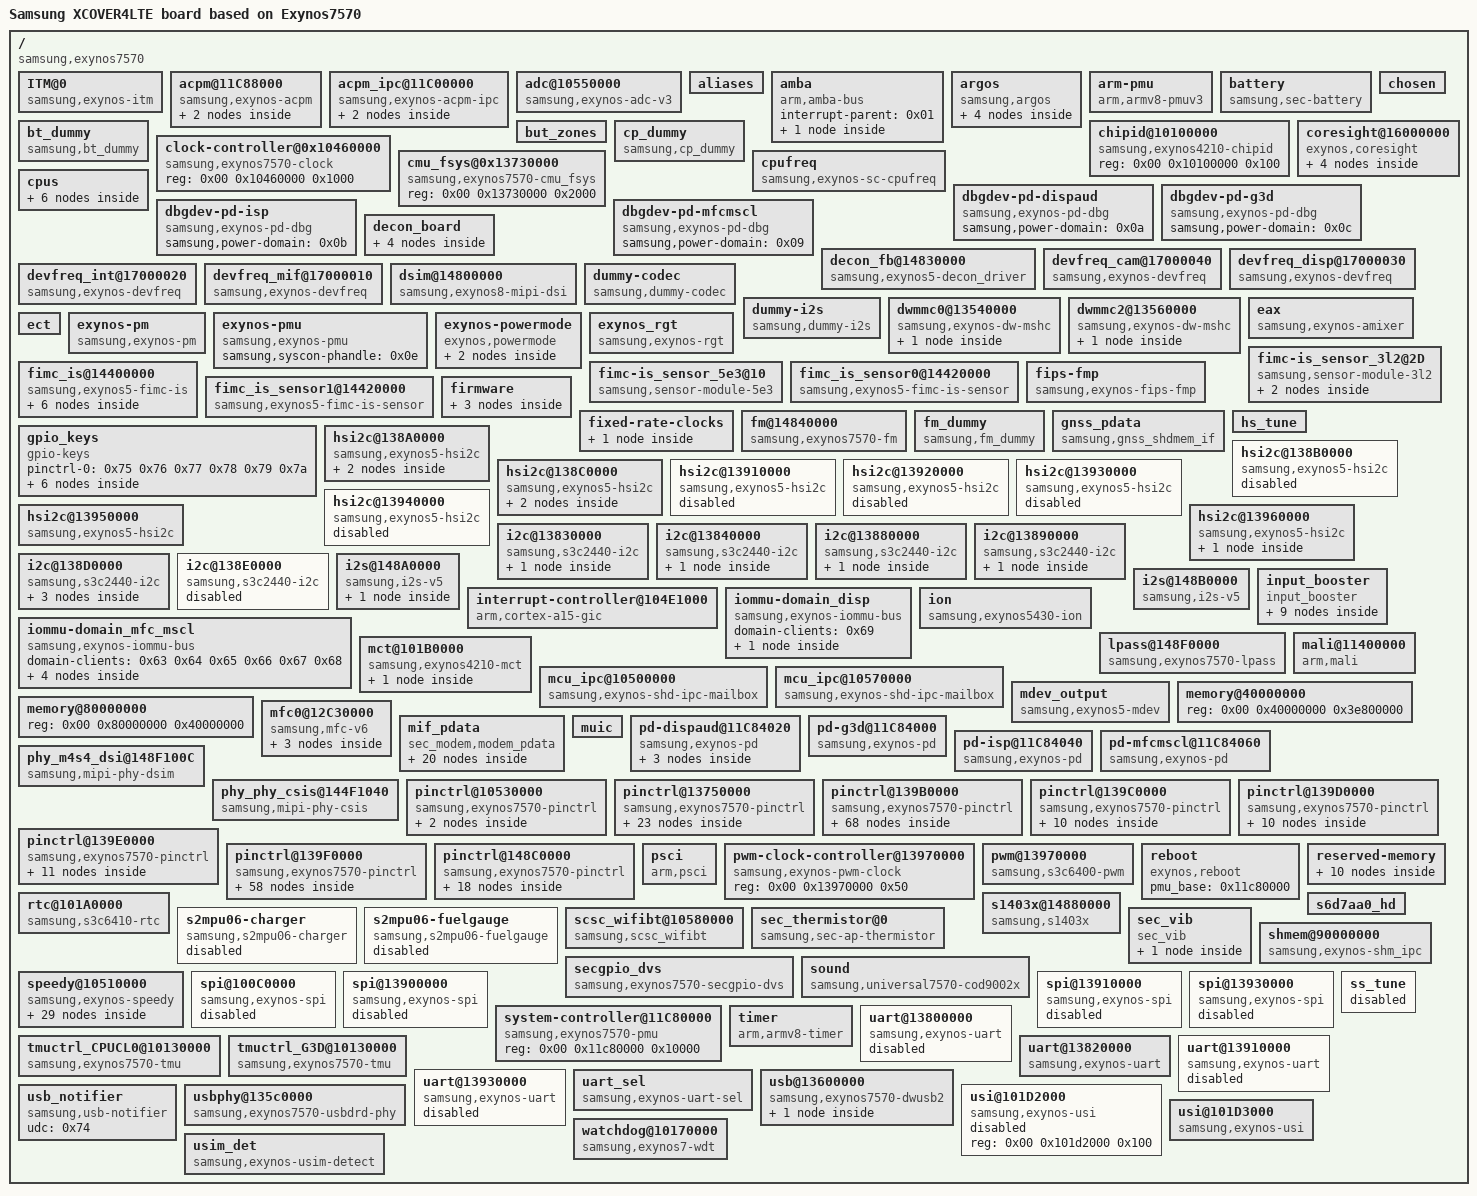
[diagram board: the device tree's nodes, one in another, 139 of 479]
/dts-v1/;

/memreserve/	0x000000007e700000 0x0000000000100000;
/ {
	#address-cells = <0x02>;
	#size-cells = <0x01>;
	compatible = "samsung,exynos7570\0samsung,exynos4210";
	interrupt-parent = <0x01>;
	model = "Samsung XCOVER4LTE board based on Exynos7570";
	model_info-chip = <0x1d92>;
	model_info-hw_rev = <0x00>;
	model_info-hw_rev_end = <0x00>;
	model_info-platform = "android";
	model_info-subtype = "samsung";

	ITM@0 {
		compatible = "samsung,exynos-itm";
	};

	acpm@11C88000 {
		#address-cells = <0x02>;
		#size-cells = <0x01>;
		compatible = "samsung,exynos-acpm";
		debug_logging_level = <0x00>;
		dump_base = <0x2046000>;
		dump_size = <0x3800>;
		log_base = <0x2047700>;
		log_buff_len = <0x17c>;
		log_buff_size = <0x10>;
		logging_period = <0x1f4>;
		reg = <0x00 0x11c88000 0x1000>;
		time_len = <0x20>;

		plugins {

			framework {
				acpm-ipc-channel = <0x80>;
				attach = <0x02>;
				id = <0x00>;
			};
		};
	};

	acpm_ipc@11C00000 {
		#address-cells = <0x02>;
		#size-cells = <0x01>;
		compatible = "samsung,exynos-acpm-ipc";
		interrupts = <0x00 0x16 0x00>;
		reg = <0x00 0x11c00000 0x1000>;

		channels {
			max_buff_size = <0x300>;
			polling = <0x01>;

			framework@0x02047400 {
				buff_len = <0x08>;
				buff_size = <0x0c>;
				channel_id = <0x00>;
				direction_buff = <0x19c>;
				linux,phandle = <0x80>;
				phandle = <0x80>;
				rx_buff = <0x2047400>;
				tx_buff = <0x2047480>;
			};
		};
	};

	adc@10550000 {
		#io-channel-cells = <0x01>;
		clock-names = "gate_adcif";
		clocks = <0x10 0x0a>;
		compatible = "samsung,exynos-adc-v3";
		interrupts = <0x00 0x18b 0x00>;
		io-channel-ranges;
		linux,phandle = <0x43>;
		phandle = <0x43>;
		reg = <0x00 0x10550000 0x1000>;
	};

	aliases {
		decon0 = "/decon_fb@14830000";
		dsim0 = "/dsim@14800000";
		hsi2c0 = "/hsi2c@13950000";
		hsi2c1 = "/hsi2c@13960000";
		hsi2c2 = "/hsi2c@138A0000";
		hsi2c3 = "/hsi2c@138C0000";
		hsi2c4 = "/hsi2c@138B0000";
		hsi2c5 = "/hsi2c@13910000";
		hsi2c6 = "/hsi2c@13920000";
		hsi2c7 = "/hsi2c@13930000";
		hsi2c8 = "/hsi2c@13940000";
		mfc0 = "/mfc0@12C30000";
		mshc0 = "/dwmmc0@13540000";
		mshc2 = "/dwmmc2@13560000";
		pinctrl0 = "/pinctrl@139F0000";
		pinctrl1 = "/pinctrl@148C0000";
		pinctrl2 = "/pinctrl@139E0000";
		pinctrl3 = "/pinctrl@13750000";
		pinctrl4 = "/pinctrl@10530000";
		pinctrl5 = "/pinctrl@139C0000";
		pinctrl6 = "/pinctrl@139B0000";
		pinctrl7 = "/pinctrl@139D0000";
		scaler0 = "/iommu-domain_mfc_mscl/scaler@12C10000";
		spi0 = "/spi@100C0000";
		spi1 = "/spi@13900000";
		spi2 = "/spi@13910000";
		spi3 = "/spi@13930000";
		tmuctrl0 = "/tmuctrl_CPUCL0@10130000";
		tmuctrl1 = "/tmuctrl_G3D@10130000";
		uart1 = "/uart@13800000";
		uart2 = "/uart@13820000";
		uart3 = "/uart@13910000";
		uart4 = "/uart@13930000";
	};

	amba {
		#address-cells = <0x02>;
		#size-cells = <0x01>;
		compatible = "arm,amba-bus";
		interrupt-parent = <0x01>;
		ranges;

		pdma0@10490000 {
			#dma-cells = <0x01>;
			#dma-channels = <0x08>;
			#dma-requests = <0x20>;
			clock-names = "apb_pclk";
			clocks = <0x10 0x32>;
			compatible = "arm,pl330\0arm,primecell";
			interrupts = <0x00 0x17f 0x00>;
			linux,phandle = <0x3c>;
			phandle = <0x3c>;
			reg = <0x00 0x10490000 0x1000>;
		};
	};

	argos {
		#address-cells = <0x01>;
		compatible = "samsung,argos";

		boot_device@1 {
			net_boost,label = "IPC";
			net_boost,node = "rmnet0 rmnet1 rmnet2 rmnet3 rmnet4 rmnet5 rmnet6 rmnet7 umts_dm0";
			net_boost,table = <0x01 0x00 0x00 0x00 0x00 0x00 0x01 0x14 0xca648 0x00 0x65900 0x186a0 0x00 0x01 0x32 0xfde80 0x00 0xc96a8 0x186a0 0x00 0x01 0x64 0x15d1f0 0x00 0xc96a8 0x186a0 0x00 0x01>;
			net_boost,table_size = <0x04>;
		};

		boot_device@2 {
			net_boost,label = "USB";
			net_boost,node = "rndis0";
			net_boost,table = <0x01 0x00 0x00 0x00 0x00 0x00 0x01>;
			net_boost,table_size = <0x01>;
		};

		boot_device@3 {
			net_boost,label = "P2P";
			net_boost,node = "p2p-wlan0-0";
			net_boost,table = <0x1e 0x137090 0x00 0x65518 0x00 0x00 0x00 0x32 0x1506d0 0x00 0x65518 0x00 0x00 0x00 0x5a 0x1506d0 0x00 0xa2990 0x00 0x01 0x01>;
			net_boost,table_size = <0x03>;
		};

		boot_device@4 {
			net_boost,label = "WIFI";
			net_boost,node = "wlan0";
			net_boost,table = <0x0a 0xfde80 0x00 0x65518 0x00 0x00 0x00 0x3c 0x1506d0 0x00 0xa2990 0x00 0x01 0x01 0x78 0x1506d0 0x00 0xa2990 0x00 0x01 0x01>;
			net_boost,table_size = <0x03>;
		};
	};

	arm-pmu {
		compatible = "arm,armv8-pmuv3";
		interrupts = <0x00 0x32 0x04 0x00 0x33 0x04 0x00 0x34 0x04 0x00 0x35 0x04>;
	};

	battery {
		#io-channel-cells = <0x01>;
		battery,adc_check_count = <0x05>;
		battery,age_data = <0x00 0x10fe 0x10b8 0x109a 0x5d 0x1c 0x10ea 0x10a4 0x1086 0x5b 0x24 0x10d6 0x1090 0x1072 0x59>;
		battery,battery_check_type = <0x05>;
		battery,battery_full_capacity = <0xaf0>;
		battery,cable_check_type = <0x04>;
		battery,cable_source_type = <0x01>;
		battery,call_event_siop_level = <0x32>;
		battery,charger_name = "s2mpu06-charger";
		battery,charging_reset_time = <0x00>;
		battery,charging_total_time = <0x5460>;
		battery,check_adc_max = <0x5a0>;
		battery,check_adc_min = <0x00>;
		battery,check_count = <0x00>;
		battery,chg_charging_limit_current = <0x514>;
		battery,chg_charging_limit_current_2nd = <0x514>;
		battery,chg_float_voltage = <0x10fe>;
		battery,chg_gpio_full_check = <0x00>;
		battery,chg_high_temp_1st = <0x212>;
		battery,chg_high_temp_2nd = <0x212>;
		battery,chg_high_temp_recovery = <0x20d>;
		battery,chg_polarity_full_check = <0x01>;
		battery,chg_skip_check_capacity = <0x0a>;
		battery,chg_skip_check_time = <0x258>;
		battery,chip_vendor = "LSI";
		battery,enable_water_resistance;
		battery,expired_time = <0x35e8>;
		battery,fast_charging_current = <0x708 0x00 0x00 0x708 0x1cc 0x4b0 0x3e8 0x1cc 0x4b0 0x00 0x4b0 0x4b0 0x4b0 0x4b0 0x4b0 0x00 0x00 0x190 0x2bc 0x4b0 0x12c 0x3e8 0x4b0 0x00 0x708 0x708 0x3e8 0x708 0x50 0x708 0x3e8 0x578 0x00 0x3e8 0x4b0 0x4b0 0x00>;
		battery,fuelgauge_name = "s2mpu06-fuelgauge";
		battery,full_check_count = <0x01>;
		battery,full_check_current_1st = <0x118 0x00 0x00 0x118 0x118 0x118 0x118 0x118 0x118 0x00 0x118 0x118 0x118 0x118 0x118 0x00 0x00 0x118 0x118 0x118 0x118 0x118 0x118 0x00 0x118 0x118 0x118 0x118 0x00 0x118 0x118 0x118 0x00 0x118 0x118 0x118 0x00>;
		battery,full_check_current_2nd = <0x8c 0x00 0x00 0x8c 0x8c 0x8c 0x8c 0x8c 0x8c 0x00 0x8c 0x8c 0x8c 0x8c 0x8c 0x00 0x00 0x8c 0x8c 0x8c 0x8c 0x8c 0x8c 0x00 0x8c 0x8c 0x8c 0x8c 0x00 0x8c 0x8c 0x8c 0x00 0x8c 0x8c 0x8c 0x00>;
		battery,full_check_type = <0x07>;
		battery,full_check_type_2nd = <0x07>;
		battery,full_condition_soc = <0x5d>;
		battery,full_condition_type = <0x0f>;
		battery,full_condition_vcell = <0x109a>;
		battery,inbat_voltage = <0x01>;
		battery,inbat_voltage_table_adc = <0xc30 0xc1d 0xbf5 0xbde 0xbb9 0xb8c 0xb68 0xb47 0xb28 0xafe 0xae9 0xac2 0xaa0 0xa75 0xa51 0xa35 0xa0c 0x9e3 0x9c6 0x9a3 0x984>;
		battery,inbat_voltage_table_data = <0x1b6 0x1b3 0x1ae 0x1a9 0x1a4 0x19f 0x19a 0x195 0x190 0x18b 0x186 0x181 0x17c 0x177 0x172 0x16d 0x168 0x163 0x15e 0x159 0x154>;
		battery,input_current_limit = <0x5dc 0x1cc 0x1cc 0x60e 0x1cc 0x384 0x3e8 0x1cc 0x3e8 0x00 0x334 0x334 0x334 0x3e8 0x3e8 0x00 0x00 0x190 0x2bc 0x3e8 0x12c 0x3e8 0x3e8 0x00 0x3e8 0x60e 0x3e8 0x60e 0x50 0x60e 0x3e8 0x3e8 0x3e8 0x3e8 0x334 0x334 0x1cc>;
		battery,monitor_initial_count = <0x00>;
		battery,ovp_uvlo_check_type = <0x03>;
		battery,polling_time = <0x0a 0x1e 0x1e 0x1e 0xe10>;
		battery,polling_type = <0x01>;
		battery,recharge_check_count = <0x02>;
		battery,recharge_condition_soc = <0x62>;
		battery,recharge_condition_type = <0x04>;
		battery,recharge_condition_vcell = <0x10b8>;
		battery,recharging_expired_time = <0x1518>;
		battery,recharging_total_time = <0x1518>;
		battery,standard_curr = <0x643>;
		battery,swelling_block_time = <0x258>;
		battery,swelling_drop_float_voltage = <0x1036>;
		battery,swelling_high_rechg_voltage = <0xfa0>;
		battery,swelling_high_temp_block = <0x19a>;
		battery,swelling_high_temp_current = <0x3e8>;
		battery,swelling_high_temp_recov = <0x186>;
		battery,swelling_high_temp_topoff = <0x8c>;
		battery,swelling_low_rechg_voltage = <0xfa0>;
		battery,swelling_low_temp_2step_mode = <0x01>;
		battery,swelling_low_temp_block_1st = <0x96>;
		battery,swelling_low_temp_block_2nd = <0x32>;
		battery,swelling_low_temp_current = <0x294>;
		battery,swelling_low_temp_recov_1st = <0xc8>;
		battery,swelling_low_temp_recov_2nd = <0x64>;
		battery,swelling_low_temp_topoff = <0x8c>;
		battery,technology = <0x02>;
		battery,temp_adc_type = <0x01>;
		battery,temp_check_count = <0x01>;
		battery,temp_check_type = <0x02>;
		battery,temp_high_recovery_lpm = <0x1c2>;
		battery,temp_high_recovery_normal = <0x1c2>;
		battery,temp_high_threshold_lpm = <0x1f4>;
		battery,temp_high_threshold_normal = <0x1f4>;
		battery,temp_highlimit_recovery_lpm = <0x2ee>;
		battery,temp_highlimit_recovery_normal = <0x2ee>;
		battery,temp_highlimit_threshold_lpm = <0x320>;
		battery,temp_highlimit_threshold_normal = <0x320>;
		battery,temp_low_recovery_lpm = <0x32>;
		battery,temp_low_recovery_normal = <0x32>;
		battery,temp_low_threshold_lpm = <0x00>;
		battery,temp_low_threshold_normal = <0x00>;
		battery,temp_table_adc = <0x12c 0x162 0x196 0x1d9 0x22a 0x288 0x2fd 0x345 0x37e 0x3b8 0x40b 0x467 0x4a2 0x4f5 0x53c 0x55e 0x5ae 0x5fe 0x626 0x6ea 0x7d9 0x8c6 0x9b4 0xa05 0xa8a 0xafc 0xb55 0xbb5 0xc28 0xcaa 0xce0 0xd71 0xdf9 0xe62>;
		battery,temp_table_data = <0x384 0x352 0x320 0x2ee 0x2bc 0x28a 0x258 0x23a 0x226 0x212 0x1f4 0x1d6 0x1c2 0x1ae 0x19a 0x190 0x17c 0x168 0x15e 0x12c 0xfa 0xc8 0x96 0x82 0x64 0x46 0x32 0x1e 0x00 0xffffffe2 0xffffffce 0xffffff9c 0xffffff6a 0xffffff38>;
		battery,thermal_source = <0x02>;
		battery,vendor = "SDI SDI";
		battery,wireless_cc_cv = <0x56>;
		battery,wpc_charging_limit_current = <0x1c2>;
		battery,wpc_high_temp = <0x1a4>;
		battery,wpc_high_temp_recovery = <0x19a>;
		compatible = "samsung,sec-battery";
		io-channel-names = "adc-temp";
		io-channel-ranges;
		io-channels = <0x43 0x01>;
		pinctrl-names = "default";
		status = "okay";
	};

	bt_dummy {
		compatible = "samsung,bt_dummy";
		linux,phandle = <0x83>;
		phandle = <0x83>;
		status = "okay";
	};

	but_zones {
		#list-but-cells = <0x03>;
		linux,phandle = <0x44>;
		phandle = <0x44>;
	};

	chipid@10100000 {
		compatible = "samsung,exynos4210-chipid";
		reg = <0x00 0x10100000 0x100>;
	};

	chosen {
		bootargs = "console=ttySAC2,115200 clk_ignore_unused androidboot.hardware=samsungexynos7570 androidboot.selinux=disabled firmware_class.path=/vendor/firmware ess_setup=0x46000000 bcm_setup=0xffffff80f8e00000 androidboot.debug_level=0x4948 reserve-fimc=0";
		linux,initrd-end = <0x421fffff>;
		linux,initrd-start = <0x42000000>;
	};

	clock-controller@0x10460000 {
		#clock-cells = <0x01>;
		compatible = "samsung,exynos7570-clock";
		linux,phandle = <0x10>;
		phandle = <0x10>;
		reg = <0x00 0x10460000 0x1000>;
	};

	cmu_fsys@0x13730000 {
		compatible = "samsung,exynos7570-cmu_fsys\0syscon";
		linux,phandle = <0x62>;
		phandle = <0x62>;
		reg = <0x00 0x13730000 0x2000>;
	};

	coresight@16000000 {
		base = <0x16000000>;
		compatible = "exynos,coresight";
		sjtag-offset = <0x6000>;

		cs_apollo0@400000 {
			dbg-offset = <0x410000>;
			device_type = "cs";
		};

		cs_apollo1@500000 {
			dbg-offset = <0x510000>;
			device_type = "cs";
		};

		cs_apollo2@600000 {
			dbg-offset = <0x610000>;
			device_type = "cs";
		};

		cs_apollo3@700000 {
			dbg-offset = <0x710000>;
			device_type = "cs";
		};
	};

	cp_dummy {
		compatible = "samsung,cp_dummy";
		linux,phandle = <0x82>;
		phandle = <0x82>;
		status = "okay";
	};

	cpufreq {
		cl0_boot_lock_time = <0x2625a00>;
		cl0_boot_max_qos = <0x1506d0>;
		cl0_boot_min_qos = <0x1506d0>;
		cl0_dvfs_domain_name = "dvfs_cpucl0";
		cl0_en_ema = <0x00>;
		cl0_idx_num = <0x11>;
		cl0_max_support_idx = <0x05>;
		cl0_min_support_idx = <0x0e>;
		cl0_regulator = "BUCK1";
		compatible = "samsung,exynos-sc-cpufreq";
	};

	cpus {
		#address-cells = <0x02>;
		#size-cells = <0x00>;

		cpu@0 {
			compatible = "arm,cortex-a53\0arm,armv8";
			cpu-idle-states = <0x0d>;
			device_type = "cpu";
			enable-method = "psci";
			reg = <0x00 0x00>;
		};

		cpu@1 {
			compatible = "arm,cortex-a53\0arm,armv8";
			cpu-idle-states = <0x0d>;
			device_type = "cpu";
			enable-method = "psci";
			reg = <0x00 0x01>;
		};

		cpu@2 {
			compatible = "arm,cortex-a53\0arm,armv8";
			cpu-idle-states = <0x0d>;
			device_type = "cpu";
			enable-method = "psci";
			reg = <0x00 0x02>;
		};

		cpu@3 {
			compatible = "arm,cortex-a53\0arm,armv8";
			cpu-idle-states = <0x0d>;
			device_type = "cpu";
			enable-method = "psci";
			reg = <0x00 0x03>;
		};

		idle-states {
			entry-method = "arm,psci";

			cpu-sleep {
				arm,psci-suspend-param = <0x10000>;
				compatible = "exynos,idle-state";
				desc = "cpu sleep";
				entry-latency-us = <0x23>;
				exit-latency-us = <0x5a>;
				linux,phandle = <0x0d>;
				min-residency-us = <0x2ee>;
				phandle = <0x0d>;
				status = "okay";
			};
		};
	};

	dbgdev-pd-dispaud {
		compatible = "samsung,exynos-pd-dbg";
		samsung,power-domain = <0x0a>;
	};

	dbgdev-pd-g3d {
		compatible = "samsung,exynos-pd-dbg";
		samsung,power-domain = <0x0c>;
	};

	dbgdev-pd-isp {
		compatible = "samsung,exynos-pd-dbg";
		samsung,power-domain = <0x0b>;
	};

	dbgdev-pd-mfcmscl {
		compatible = "samsung,exynos-pd-dbg";
		samsung,power-domain = <0x09>;
	};

	decon_board {
		gpio_blic_on = <0x18 0x02 0x01>;
		gpio_lcd_rst = <0x73 0x00 0x01>;
		gpio_panel_enn = <0x72 0x02 0x01>;
		gpio_panel_enp = <0x72 0x01 0x01>;
		linux,phandle = <0x61>;
		phandle = <0x61>;

		dsim_reset_panel {
			type = "delay,usleep\01000 1100\0gpio,high\0gpio_lcd_rst\0delay,usleep\01000 1100\0gpio,low\0gpio_lcd_rst\0delay,usleep\01000 1100\0gpio,high\0gpio_lcd_rst\0delay,usleep\05000 5100";
		};

		dsim_set_panel_power_disable {
			type = "delay,usleep\05000 6000\0gpio,low\0gpio_lcd_rst\0delay,usleep\05000 6000\0gpio,low\0gpio_panel_enn\0delay,usleep\05000 6000\0gpio,low\0gpio_panel_enp\0delay,usleep\015000 16000\0gpio,low\0gpio_blic_on\0delay,usleep\010000 11000\0regulator,disable\0LCD_1P8";
		};

		dsim_set_panel_power_early {
			type = "regulator,enable\0LCD_1P8\0delay,usleep\01000 2000";
		};

		dsim_set_panel_power_enable {
			type = "gpio,high\0gpio_panel_enp\0delay,usleep\05000 6000\0gpio,high\0gpio_panel_enn\0delay,usleep\010000 11000\0gpio,high\0gpio_blic_on\0delay,usleep\01000 2000";
		};
	};

	decon_fb@14830000 {
		#address-cells = <0x02>;
		#pb-id-cells = <0x00>;
		#size-cells = <0x01>;
		clock-names = "decon_core\0vclk_user\0vclk_leaf";
		clocks = <0x10 0x2bf 0x10 0x2da 0x10 0x2db>;
		compatible = "samsung,exynos5-decon_driver";
		default_win = <0x00>;
		disp-dvfs = <0xc65d400>;
		disp-vclk = <0xbebc200>;
		dsi_mode = <0x00>;
		interrupts = <0x00 0xc9 0x00 0x00 0xca 0x00 0x00 0xcb 0x00 0x00 0x168 0x00>;
		ip_ver = <0x04>;
		linux,phandle = <0x69>;
		max_win = <0x03>;
		mif-vclk = <0xbebc200>;
		n_sink_pad = <0x03>;
		n_src_pad = <0x01>;
		phandle = <0x69>;
		psr_mode = <0x00>;
		ranges;
		reg = <0x00 0x14830000 0x8000>;
		samsung,power-domain = <0x5e>;
		trig_mode = <0x01>;
		vclk-denom = <0x1a1>;
		vclk-num = <0x400>;
	};

	devfreq_cam@17000040 {
		boot_qos_timeout = <0x00>;
		clock-names = "dvfs_cam";
		clocks = <0x10 0x3eb>;
		compatible = "samsung,exynos-devfreq";
		devfreq_domain_name = "dvfs_cam";
		devfreq_type = "cam";
		freq_info = <0x6c660 0x6c660 0x6c660 0x6c660 0x87410 0x6c660>;
		gov_name = "interactive";
		polling_ms = <0x00>;
		reg = <0x00 0x17000040 0x00>;
		reg_name = "BUCK1";
		use_cl_dvfs = "false";
		use_delay_time = "false";
		use_get_dev = "false";
		use_pd_off = "true";
		use_reg = "true";
		use_sw_clk = "false";
		use_tmu = "true";
		volt_info = <0x61a8 0x1312d0 0x00 0x13d620>;
	};

	devfreq_disp@17000030 {
		boot_qos_timeout = <0x28>;
		clock-names = "dvfs_disp";
		clocks = <0x10 0x3ec>;
		compatible = "samsung,exynos-devfreq";
		devfreq_domain_name = "dvfs_disp";
		devfreq_type = "disp";
		freq_info = <0x32c80 0x32c80 0x32c80 0x32c80 0x32c80 0x32c80>;
		gov_name = "interactive";
		polling_ms = <0x00>;
		reg = <0x00 0x17000030 0x00>;
		reg_name = "BUCK1";
		use_cl_dvfs = "false";
		use_delay_time = "false";
		use_get_dev = "false";
		use_pd_off = "false";
		use_reg = "true";
		use_sw_clk = "false";
		use_tmu = "true";
		volt_info = <0x61a8 0x1312d0 0x00 0x13d620>;
	};

	devfreq_int@17000020 {
		boot_qos_timeout = <0x28>;
		clock-names = "dvfs_int";
		clocks = <0x10 0x3ea>;
		compatible = "samsung,exynos-devfreq";
		devfreq_domain_name = "dvfs_int";
		devfreq_type = "int";
		freq_info = <0x72038 0x65518 0x72038 0x65518 0x72038 0x65518>;
		gov_name = "interactive";
		polling_ms = <0x00>;
		reg = <0x00 0x17000020 0x00>;
		reg_name = "BUCK1";
		use_cl_dvfs = "false";
		use_delay_time = "false";
		use_get_dev = "false";
		use_pd_off = "false";
		use_reg = "true";
		use_sw_clk = "false";
		use_tmu = "true";
		volt_info = <0x61a8 0x1312d0 0x00 0x13d620>;
	};

	devfreq_mif@17000010 {
		boot_qos_timeout = <0x28>;
		clock-names = "dvfs_mif\0dvfs_mif_sw";
		clocks = <0x10 0x3e8 0x10 0x3e9>;
		compatible = "samsung,exynos-devfreq";
		delay_time_list = "20";
		devfreq_domain_name = "dvfs_mif";
		devfreq_type = "mif";
		freq_info = <0xa2990 0x65518 0x65518 0x65518 0xa2990 0x65518>;
		gov_name = "interactive";
		polling_ms = <0x00>;
		reg = <0x00 0x17000010 0x00>;
		reg_name = "BUCK1";
		use_cl_dvfs = "false";
		use_delay_time = "true";
		use_get_dev = "false";
		use_pd_off = "false";
		use_reg = "true";
		use_sw_clk = "true";
		use_tmu = "true";
		volt_info = <0x61a8 0x1312d0 0x00 0x13d620>;
	};

	dsim@14800000 {
		clock-names = "dsim_pclk\0dphy_escclk\0dphy_byteclk";
		clocks = <0x10 0x2c0 0x10 0x2d1 0x10 0x2d0>;
		compatible = "samsung,exynos8-mipi-dsi";
		data_lane_cnt = <0x04>;
		decon_board = <0x61>;
		interrupts = <0x00 0xcf 0x00>;
		lcd_info = <0x60>;
		phy-names = "dsim_dphy";
		phys = <0x5f 0x00>;
		reg = <0x00 0x14800000 0x100>;
		samsung,power-domain = <0x5e>;
		status = "okay";
	};

	dummy-codec {
		compatible = "samsung,dummy-codec";
		linux,phandle = <0x87>;
		phandle = <0x87>;
		status = "okay";
	};

	dummy-i2s {
		compatible = "samsung,dummy-i2s";
		status = "okay";
	};

	dwmmc0@13540000 {
		#address-cells = <0x01>;
		#size-cells = <0x00>;
		broken-card-detect;
		card-detect-delay = <0xc8>;
		card-init-hwacg-ctrl;
		ciu_clkin = <0x19 0x2b 0x2b 0x19 0x2b 0x57 0xaf 0x2b 0x2b 0xaf 0xaf 0xaf>;
		clk-drive-number = <0x04>;
		clock-frequency = <0x29b92700>;
		clock-gate;
		clock-names = "biu\0ciu\0ciu_gate";
		clocks = <0x10 0x201 0x10 0x203 0x10 0x1e>;
		compatible = "samsung,exynos-dw-mshc";
		data-timeout = <0xc8>;
		desc-size = <0x04>;
		enable-ulp-mode;
		fifo-depth = <0x40>;
		fixed_voltage;
		hto-timeout = <0x50>;
		interrupts = <0x00 0xf5 0x00>;
		mmc-ddr-1_8v;
		mmc-hs200-1_8v;
		mmc-hs400-1_8v;
		mmc_pwr_shut_down;
		non-removable;
		num-ref-clks = <0x0c>;
		num-slots = <0x01>;
		pinctrl-0 = <0x4b 0x4c 0x4d 0x4e 0x4f 0x50>;
		pinctrl-1 = <0x51>;
		pinctrl-2 = <0x52>;
		pinctrl-3 = <0x53>;
		pinctrl-4 = <0x54>;
		pinctrl-names = "default\0fast-slew-rate-1x\0fast-slew-rate-2x\0fast-slew-rate-3x\0fast-slew-rate-4x";
		pm-skip-mmc-resume-init;
		reg = <0x00 0x13540000 0x2000>;
		samsung,dw-mshc-ciu-div = <0x03>;
		samsung,dw-mshc-ddr-timing = <0x03 0x00 0x04 0x02>;
		samsung,dw-mshc-ddr200-delay-line = <0x60>;
		samsung,dw-mshc-ddr200-timing = <0x01 0x00 0x04 0x00>;
		samsung,dw-mshc-ddr200-ulp-timing = <0x03 0x00 0x03 0x00>;
		samsung,dw-mshc-hs200-timing = <0x03 0x00 0x03 0x00>;
		samsung,dw-mshc-sdr-timing = <0x03 0x00 0x02 0x00>;
		samsung,dw-mshc-txdt-crc-timer-fastlimit = <0x34>;
		samsung,dw-mshc-txdt-crc-timer-initval = <0x38>;
		status = "okay";
		supports-8bit;
		supports-cmd23;
		supports-erase;
		supports-highspeed;
		supports-hs400-enhanced-strobe;
		use-smu;

		slot@0 {
			bus-width = <0x08>;
			reg = <0x00>;
		};
	};

	dwmmc2@13560000 {
		#address-cells = <0x01>;
		#size-cells = <0x00>;
		bypass-for-allpass;
		bypass-smu;
		card-detect = <0x22 0x01 0x0f>;
		card-detect-delay = <0xc8>;
		card-detect-gpio;
		card-init-hwacg-ctrl;
		ciu_clkin = <0x19 0x2b 0x2b 0x19 0x2b 0x57 0xaf 0x2b 0x2b>;
		clk-drive-number = <0x04>;
		clock-frequency = <0x29b92700>;
		clock-gate;
		clock-names = "biu\0ciu\0ciu_gate";
		clocks = <0x10 0x202 0x10 0x204 0x10 0x1f>;
		compatible = "samsung,exynos-dw-mshc";
		data-timeout = <0xc8>;
		desc-size = <0x04>;
		fifo-depth = <0x40>;
		hto-timeout = <0x50>;
		ignore-phase = <0x80>;
		interrupts = <0x00 0xf7 0x00>;
		num-ref-clks = <0x09>;
		num-slots = <0x01>;
		only_once_tune;
		pinctrl-0 = <0x55 0x56 0x57 0x58 0x59>;
		pinctrl-1 = <0x5a>;
		pinctrl-2 = <0x5b>;
		pinctrl-3 = <0x5c>;
		pinctrl-4 = <0x5d>;
		pinctrl-names = "default\0fast-slew-rate-1x\0fast-slew-rate-2x\0fast-slew-rate-3x\0fast-slew-rate-4x";
		reg = <0x00 0x13560000 0x2000>;
		samsung,dw-mshc-ciu-div = <0x03>;
		samsung,dw-mshc-ddr-timing = <0x03 0x00 0x02 0x01>;
		samsung,dw-mshc-sdr-timing = <0x03 0x00 0x02 0x00>;
		samsung,dw-mshc-sdr104-timing = <0x03 0x00 0x03 0x00>;
		samsung,dw-mshc-sdr50-timing = <0x03 0x00 0x04 0x02>;
		sd-uhs-sdr104;
		sd-uhs-sdr50;
		sec-sd-slot-type = <0x01>;
		skip-init-mmc-scan;
		status = "okay";
		supports-4bit;
		supports-cmd23;
		supports-erase;
		supports-highspeed;
		switch_transfer;
		use-fine-tuning;

		slot@0 {
			bus-width = <0x04>;
			disable-wp;
			reg = <0x00>;
		};
	};

	eax {
		compatible = "samsung,exynos-amixer";
		linux,phandle = <0x86>;
		phandle = <0x86>;
		status = "ok";
	};

	ect {
		parameter_address = <0x7e0fa000>;
		parameter_size = <0x6000>;
	};

	exynos-pm {
		compatible = "samsung,exynos-pm";
		cp_call_mode_idx = <0x04>;
		cp_call_psci_idx = <0x84>;
		num-eint = <0x18>;
		num-gic = <0x10>;
		reg = <0x00 0x139f0000 0x1000 0x00 0x104e1200 0x100>;
		reg-names = "gpio_alive_base\0gicd_ispendrn_base";
		suspend_mode_idx = <0x08>;
		suspend_psci_idx = <0x83>;
	};

	exynos-pmu {
		compatible = "samsung,exynos-pmu";
		samsung,syscon-phandle = <0x0e>;
	};

	exynos-powermode {
		compatible = "exynos,powermode";
		cpd_residency = <0xbb8>;
		idle-ip = "136c0000.pwm\010550000.adc\010510000.hsi2c\013950000.hsi2c\013960000.hsi2c\0138a0000.hsi2c\0138b0000.hsi2c\0138c0000.hsi2c\0138f0000.hsi2c\013870000.i2c\013880000.i2c\013890000.i2c\013840000.i2c\013830000.i2c\0138d0000.i2c\0138e0000.i2c\013850000.i2c\013860000.i2c\013540000.dwmmc0\013560000.dwmmc2\013600000.usb\0100c0000.spi\013900000.spi\013910000.spi\013920000.spi\013930000.spi\010500000.mailbox-cp\010570000.mailbox-gnss\014830000.decon_fb\0pd-g3d\0pd-isp\0pd-mfcmscl\0148f0000.lpass";
		sicd_enabled = <0x00>;
		sicd_residency = <0xbb8>;
		wakeup_mask = <0x400f91e1 0x00 0x00 0x00 0x00 0x00 0x00 0x00 0x400ffffe>;
		wakeup_mask2 = <0x00 0x00 0x00 0x00 0x00 0x00 0x00 0x00 0xffff00ff>;
		wakeup_mask3 = <0x00 0x00 0x00 0x00 0x00 0x00 0x00 0x00 0xffff00ff>;

		idle_ip_mask {

			SYS_SICD {
				mode-index = <0x00>;
				ref-idle-ip = <0x00 0x01 0x02 0x03 0x04 0x05 0x06 0x07 0x08 0x09 0x0a 0x0b 0x0c 0x0d 0x0e 0x0f 0x10 0x11 0x12 0x13 0x14 0x15 0x16 0x17 0x18 0x19 0x1a 0x1b 0x1c 0x1d 0x1e 0x1f 0x20>;
			};
		};
	};

	exynos_rgt {
		compatible = "samsung,exynos-rgt";
	};

	fimc-is_sensor_3l2@2D {
		compatible = "samsung,sensor-module-3l2";
		gpio_reset = <0x1f 0x01 0x01>;
		id = <0x00>;
		mclk_ch = <0x00>;
		pinctrl-0;
		pinctrl-1 = <0x7b 0x7c>;
		pinctrl-2 = <0x7d 0x7c>;
		pinctrl-names = "pin0\0pin1\0pin2";
		position = <0x00>;
		sensor_i2c_addr = <0x2d>;
		sensor_i2c_ch = <0x00>;
		status = "okay";

		af {
			i2c_addr = <0x0c>;
			i2c_ch = <0x01>;
			product_name = <0x0e>;
		};

		flash {
			flash_first_gpio = <0x02>;
			flash_second_gpio = <0x01>;
			product_name = <0x0d>;
		};
	};

	fimc-is_sensor_5e3@10 {
		compatible = "samsung,sensor-module-5e3";
		gpio_reset = <0x1f 0x06 0x01>;
		id = <0x01>;
		mclk_ch = <0x00>;
		pinctrl-0;
		pinctrl-1 = <0x7b>;
		pinctrl-2 = <0x7d>;
		pinctrl-names = "pin0\0pin1\0pin2";
		position = <0x01>;
		sensor_i2c_addr = <0x10>;
		sensor_i2c_ch = <0x00>;
		status = "okay";
	};

	fimc_is@14400000 {
		#pb-id-cells = <0x00>;
		clock-names = "oscclk\0isp_ppmu\0isp_bts\0isp_cam\0isp_vra\0umux_isp_clkphy_isp_s_rxbyteclkhs0_s4_user\0gate_mscl\0mif_isp_sensor0";
		clocks = <0x10 0x01 0x10 0x321 0x10 0x322 0x10 0x323 0x10 0x324 0x10 0x32a 0x10 0x262 0x10 0x2b>;
		compatible = "samsung,exynos5-fimc-is";
		interrupts = <0x00 0x8b 0x00 0x00 0x8c 0x00 0x00 0x8d 0x00 0x00 0x8e 0x00 0x00 0x92 0x00 0x00 0x190 0x00>;
		linux,phandle = <0x66>;
		phandle = <0x66>;
		reg = <0x00 0x14400000 0xc400 0x00 0x14430000 0x2000 0x00 0x14440000 0x10000 0x00 0x14450000 0x10000 0x00 0x14480000 0xc400 0x00 0x12c00000 0x2000>;
		samsung,power-domain = <0x0b>;
		status = "ok";

		fimc_is_dvfs {

			table0 {
				default_cam = <0x87410>;
				default_i2c = <0x00>;
				default_int = <0x72038>;
				default_mif = <0xcaa30>;
				desc = "HAL1 version";
				front_capture_cam = <0x6c660>;
				front_capture_i2c = <0x00>;
				front_capture_int = <0x72038>;
				front_capture_mif = <0xcaa30>;
				front_preview_cam = <0x6c660>;
				front_preview_i2c = <0x00>;
				front_preview_int = <0x72038>;
				front_preview_mif = <0xcaa30>;
				front_video_cam = <0x6c660>;
				front_video_capture_cam = <0x6c660>;
				front_video_capture_i2c = <0x00>;
				front_video_capture_int = <0x72038>;
				front_video_capture_mif = <0xcaa30>;
				front_video_i2c = <0x00>;
				front_video_int = <0x72038>;
				front_video_mif = <0xcaa30>;
				front_vt1_cam = <0x6c660>;
				front_vt1_i2c = <0x00>;
				front_vt1_int = <0x72038>;
				front_vt1_mif = <0xcaa30>;
				front_vt2_cam = <0x6c660>;
				front_vt2_i2c = <0x00>;
				front_vt2_int = <0x72038>;
				front_vt2_mif = <0xcaa30>;
				max_cam = <0xa2990>;
				max_i2c = <0x00>;
				max_int = <0x72038>;
				max_mif = <0xcaa30>;
				preview_high_speed_fps_cam = <0x87410>;
				preview_high_speed_fps_i2c = <0x00>;
				preview_high_speed_fps_int = <0x72038>;
				preview_high_speed_fps_mif = <0xcaa30>;
				rear_capture_cam = <0x87410>;
				rear_capture_i2c = <0x00>;
				rear_capture_int = <0x72038>;
				rear_capture_mif = <0xcaa30>;
				rear_preview_cam = <0x87410>;
				rear_preview_i2c = <0x00>;
				rear_preview_int = <0x72038>;
				rear_preview_mif = <0xcaa30>;
				rear_video_cam = <0x87410>;
				rear_video_capture_cam = <0x87410>;
				rear_video_capture_i2c = <0x00>;
				rear_video_capture_int = <0x72038>;
				rear_video_capture_mif = <0xcaa30>;
				rear_video_i2c = <0x00>;
				rear_video_int = <0x72038>;
				rear_video_mif = <0xcaa30>;
				video_high_speed_120fps_cam = <0x87410>;
				video_high_speed_120fps_i2c = <0x00>;
				video_high_speed_120fps_int = <0x72038>;
				video_high_speed_120fps_mif = <0xcaa30>;
				video_high_speed_60fps_cam = <0x87410>;
				video_high_speed_60fps_i2c = <0x00>;
				video_high_speed_60fps_int = <0x72038>;
				video_high_speed_60fps_mif = <0xcaa30>;
			};

			table1 {
				default_cam = <0x87410>;
				default_i2c = <0x00>;
				default_int = <0x72038>;
				default_mif = <0xcaa30>;
				desc = "HAL3 version";
				front_capture_cam = <0x6c660>;
				front_capture_i2c = <0x00>;
				front_capture_int = <0x72038>;
				front_capture_mif = <0xcaa30>;
				front_preview_cam = <0x6c660>;
				front_preview_i2c = <0x00>;
				front_preview_int = <0x72038>;
				front_preview_mif = <0xcaa30>;
				front_video_cam = <0x6c660>;
				front_video_capture_cam = <0x6c660>;
				front_video_capture_i2c = <0x00>;
				front_video_capture_int = <0x72038>;
				front_video_capture_mif = <0xcaa30>;
				front_video_i2c = <0x00>;
				front_video_int = <0x72038>;
				front_video_mif = <0xcaa30>;
				front_vt1_cam = <0x6c660>;
				front_vt1_i2c = <0x00>;
				front_vt1_int = <0x72038>;
				front_vt1_mif = <0xcaa30>;
				front_vt2_cam = <0x6c660>;
				front_vt2_i2c = <0x00>;
				front_vt2_int = <0x72038>;
				front_vt2_mif = <0xcaa30>;
				max_cam = <0xa2990>;
				max_i2c = <0x00>;
				max_int = <0x72038>;
				max_mif = <0xcaa30>;
				preview_high_speed_fps_cam = <0x87410>;
				preview_high_speed_fps_i2c = <0x00>;
				preview_high_speed_fps_int = <0x72038>;
				preview_high_speed_fps_mif = <0xcaa30>;
				rear_capture_cam = <0x87410>;
				rear_capture_i2c = <0x00>;
				rear_capture_int = <0x72038>;
				rear_capture_mif = <0xcaa30>;
				rear_preview_cam = <0x87410>;
				rear_preview_i2c = <0x00>;
				rear_preview_int = <0x72038>;
				rear_preview_mif = <0xcaa30>;
				rear_video_cam = <0x87410>;
				rear_video_capture_cam = <0x87410>;
				rear_video_capture_i2c = <0x00>;
				rear_video_capture_int = <0x72038>;
				rear_video_capture_mif = <0xcaa30>;
				rear_video_i2c = <0x00>;
				rear_video_int = <0x72038>;
				rear_video_mif = <0xcaa30>;
				video_high_speed_120fps_cam = <0x87410>;
				video_high_speed_120fps_i2c = <0x00>;
				video_high_speed_120fps_int = <0x72038>;
				video_high_speed_120fps_mif = <0xcaa30>;
				video_high_speed_60fps_cam = <0x87410>;
				video_high_speed_60fps_i2c = <0x00>;
				video_high_speed_60fps_int = <0x72038>;
				video_high_speed_60fps_mif = <0xcaa30>;
			};
		};

		vender {
			front_sensor_id = <0x11>;
			rear_sensor_id = <0x08>;
			total_camera_num = <0x02>;
			use_module_check;

			camera_info0 {
				cal_memory = <0x02>;
				companion = <0x00>;
				core_voltage = <0x00>;
				isp = <0x00>;
				ois = <0x00>;
				read_version = <0x00>;
				upgrade = <0x00>;
			};

			camera_info1 {
				cal_memory = <0x03>;
				companion = <0x00>;
				core_voltage = <0x00>;
				isp = <0x00>;
				ois = <0x00>;
				read_version = <0x00>;
				upgrade = <0x00>;
			};
		};
	};

	fimc_is_sensor0@14420000 {
		#pb-id-cells = <0x00>;
		clock-names = "mif_isp_sensor0";
		clocks = <0x10 0x2b>;
		compatible = "samsung,exynos5-fimc-is-sensor";
		csi_ch = <0x00>;
		flite_ch = <0x00>;
		id = <0x00>;
		interrupts = <0x00 0x90 0x00 0x00 0x89 0x00>;
		is_bns = <0x01>;
		linux,phandle = <0x67>;
		phandle = <0x67>;
		phy-names = "csis_dphy";
		phys = <0x6e 0x01>;
		reg = <0x00 0x14420000 0x10000 0x00 0x14410000 0x10000>;
		samsung,power-domain = <0x0b>;
		scenario = <0x00>;
		status = "okay";
	};

	fimc_is_sensor1@14420000 {
		#pb-id-cells = <0x00>;
		clock-names = "mif_isp_sensor0";
		clocks = <0x10 0x2b>;
		compatible = "samsung,exynos5-fimc-is-sensor";
		csi_ch = <0x00>;
		flite_ch = <0x00>;
		id = <0x01>;
		interrupts = <0x00 0x90 0x00 0x00 0x89 0x00>;
		is_bns = <0x01>;
		linux,phandle = <0x68>;
		phandle = <0x68>;
		phy-names = "csis_dphy";
		phys = <0x6e 0x00>;
		reg = <0x00 0x14420000 0x10000 0x00 0x14410000 0x10000>;
		samsung,power-domain = <0x0b>;
		scenario = <0x00>;
		status = "okay";
	};

	fips-fmp {
		compatible = "samsung,exynos-fips-fmp";
	};

	firmware {

		android {
			compatible = "android,firmware";

			fstab {
				compatible = "android,fstab";

				system {
					compatible = "android,system";
					dev = "/dev/block/platform/13540000.dwmmc0/by-name/SYSTEM";
					fsmgr_flags = "wait,verify";
					mnt_flags = "ro";
					type = "ext4";
				};
			};
		};
	};

	fixed-rate-clocks {

		oscclk {
			clock-frequency = <0x18cba80>;
			compatible = "samsung,exynos7570-oscclk";
		};
	};

	fm@14840000 {
		clock-names = "oscclk_fm_52m_div";
		clocks = <0x10 0x2e7>;
		compatible = "samsung,exynos7570-fm";
		elna_gpio = <0x70 0x04 0x01>;
		fm_iclk_aux = <0x00>;
		fm_tc_on = <0x00>;
		interrupts = <0x00 0xc3 0x00>;
		pinctrl-0 = <0x71>;
		pinctrl-names = "default";
		reg = <0x00 0x14840000 0x2000 0x00 0x11c80000 0x1000 0x00 0x10580000 0x100 0x00 0x148d0000 0x500 0x00 0x10460000 0x3000 0x00 0x13730000 0x2000 0x00 0x14880000 0x100>;
		samsung,power-domain = <0x6f>;
		samsung,syscon-phandle = <0x0e>;
		status = "okay";
	};

	fm_dummy {
		compatible = "samsung,fm_dummy";
		linux,phandle = <0x84>;
		phandle = <0x84>;
		status = "okay";
	};

	gnss_pdata {
		compatible = "samsung,gnss_shdmem_if";
		fault_info = <0x01 0x100000 0x100000>;
		interrupts = <0x00 0x13 0x00 0x00 0x1de 0x00 0x00 0x1dd 0x00>;
		mbx,int_ap2gnss_ack_wake_clr = <0x04>;
		mbx,int_ap2gnss_ack_wake_set = <0x03>;
		mbx,int_ap2gnss_bcmd = <0x00>;
		mbx,int_ap2gnss_ipc_msg = <0x02>;
		mbx,int_ap2gnss_req_fault_info = <0x01>;
		mbx,irq_gnss2ap_bcmd = <0x00>;
		mbx,irq_gnss2ap_ipc_msg = <0x02>;
		mbx,irq_gnss2ap_req_wake_clr = <0x04>;
		mbx,irq_gnss2ap_rsp_fault_info = <0x01>;
		mbx,reg_bcmd_ctrl = <0x00 0x01 0x02 0x03>;
		reg_rx_head = <0x01 0x03>;
		reg_rx_ipc_msg = <0x01 0x05>;
		reg_rx_tail = <0x01 0x02>;
		reg_tx_head = <0x01 0x01>;
		reg_tx_ipc_msg = <0x01 0x04>;
		reg_tx_tail = <0x01 0x00>;
		shmem,device_node_name = "gnss_ipc";
		shmem,ipc_offset = <0x180000>;
		shmem,ipc_reg_cnt = <0x20>;
		shmem,ipc_size = <0x80000>;
		shmem,name = "KEPLER";
		status = "okay";
	};

	gpio_keys {
		#address-cells = <0x01>;
		#size-cells = <0x00>;
		compatible = "gpio-keys";
		pinctrl-0 = <0x75 0x76 0x77 0x78 0x79 0x7a>;
		pinctrl-names = "default";

		button@1 {
			gpios = <0x22 0x07 0x0f>;
			interrupt-parent = <0x22>;
			interrupts = <0x07 0x00 0x00>;
			label = "gpio-keys: KEY_VOLUMEUP";
			linux,code = <0x73>;
		};

		button@2 {
			gpio-key,wakeup = <0x01>;
			gpios = <0x22 0x04 0x0f>;
			interrupt-parent = <0x22>;
			interrupts = <0x04 0x00 0x00>;
			label = "gpio-keys: KEY_HOME";
			linux,code = <0xac>;
		};

		button@3 {
			gpios = <0x2c 0x03 0x0f>;
			interrupt-parent = <0x2c>;
			interrupts = <0x03 0x00 0x00>;
			label = "gpio-keys: KEY_VOLUMEDOWN";
			linux,code = <0x72>;
		};

		button@4 {
			gpios = <0x2c 0x06 0x0f>;
			interrupt-parent = <0x2c>;
			interrupts = <0x06 0x00 0x00>;
			label = "gpio-keys: KEY_BACK";
			linux,code = <0x9e>;
		};

		button@5 {
			gpios = <0x2c 0x05 0x0f>;
			interrupt-parent = <0x2c>;
			interrupts = <0x05 0x00 0x00>;
			label = "gpio-keys: KEY_RECENT";
			linux,code = <0xfe>;
		};

		button@6 {
			gpios = <0x2c 0x07 0x0f>;
			interrupt-parent = <0x18>;
			interrupts = <0x05 0x00 0x00>;
			label = "gpio-keys: KEY_DUMMY_HOME";
			linux,code = <0xfc>;
		};
	};

	hs_tune {
		compdis = <0x03 0x03>;
		enable_user_imp = <0x00 0x00>;
		is_phyclock = <0x01>;
		linux,phandle = <0x6b>;
		otg = <0x02 0x02>;
		phandle = <0x6b>;
		rx_sqrx = <0x05 0x05>;
		status = "okay";
		tx_fsls = <0x03 0x03>;
		tx_hsxv = <0x00 0x00>;
		tx_pre_emp = <0x00 0x00>;
		tx_pre_emp_puls = <0x00 0x00>;
		tx_res = <0x02 0x02>;
		tx_rise = <0x01 0x01>;
		tx_vref = <0x03 0x03>;
	};

	hsi2c@138A0000 {
		#address-cells = <0x01>;
		#size-cells = <0x00>;
		clock-frequency = <0x61a80>;
		clock-names = "rate_hsi2c\0gate_hsi2c";
		clocks = <0x10 0x141 0x10 0x141>;
		compatible = "samsung,exynos5-hsi2c";
		gpio_scl = <0x35 0x01 0x01>;
		gpio_sda = <0x35 0x00 0x01>;
		gpios = <0x35 0x00 0x00 0x35 0x01 0x00>;
		interrupts = <0x00 0x1c1 0x00>;
		pinctrl-0 = <0x34>;
		pinctrl-1 = <0x34>;
		pinctrl-names = "default\0on_i2c";
		reg = <0x00 0x138a0000 0x1000>;
		samsung,check-transdone-int;
		samsung,scl-clk-stretching;
		status = "okay";

		fimc-is-3l2@2D {
			compatible = "samsung,exynos5-fimc-is-cis-3l2";
			id = <0x00>;
			reg = <0x2d>;
			sensor_f_number = <0x02>;
			setfile = "default";
		};

		fimc-is-5e3@10 {
			compatible = "samsung,exynos5-fimc-is-cis-5e3";
			id = <0x01>;
			reg = <0x10>;
			sensor_f_number = <0x04>;
			setfile = "default";
		};
	};

	hsi2c@138B0000 {
		#address-cells = <0x01>;
		#size-cells = <0x00>;
		clock-names = "rate_hsi2c\0gate_hsi2c";
		clocks = <0x10 0x142 0x10 0x142>;
		compatible = "samsung,exynos5-hsi2c";
		gpio_scl = <0x20 0x01 0x01>;
		gpio_sda = <0x20 0x00 0x01>;
		interrupts = <0x00 0x1c2 0x00>;
		pinctrl-0 = <0x37>;
		pinctrl-names = "default";
		reg = <0x00 0x138b0000 0x1000>;
		samsung,check-transdone-int;
		samsung,scl-clk-stretching;
		status = "disabled";
	};

	hsi2c@138C0000 {
		#address-cells = <0x01>;
		#size-cells = <0x00>;
		clock-frequency = <0x61a80>;
		clock-names = "rate_hsi2c\0gate_hsi2c";
		clocks = <0x10 0x140 0x10 0x140>;
		compatible = "samsung,exynos5-hsi2c";
		gpio_scl = <0x35 0x03 0x01>;
		gpio_sda = <0x35 0x02 0x01>;
		gpios = <0x35 0x02 0x00 0x35 0x03 0x00>;
		interrupts = <0x00 0x1c3 0x00>;
		pinctrl-0 = <0x36>;
		pinctrl-1 = <0x36>;
		pinctrl-names = "default\0on_i2c";
		reg = <0x00 0x138c0000 0x1000>;
		samsung,check-transdone-int;
		samsung,scl-clk-stretching;
		status = "okay";

		fimc-is-actuator@0C {
			compatible = "samsung,exynos5-fimc-is-actuator-zc533";
			id = <0x00>;
			reg = <0x0c>;
		};

		rear_eeprom@58 {
			compatible = "samsung,rear-eeprom-i2c";
			reg = <0x58>;
		};
	};

	hsi2c@13910000 {
		#address-cells = <0x01>;
		#size-cells = <0x00>;
		clock-names = "rate_hsi2c\0gate_hsi2c";
		clocks = <0x10 0x15f 0x10 0x15f>;
		compatible = "samsung,exynos5-hsi2c";
		gpio_scl = <0x2c 0x00 0x01>;
		gpio_sda = <0x18 0x07 0x01>;
		interrupts = <0x00 0x1cb 0x00>;
		pinctrl-0 = <0x3d>;
		pinctrl-names = "default";
		reg = <0x00 0x13910000 0x1000>;
		samsung,check-transdone-int;
		samsung,scl-clk-stretching;
		status = "disabled";
	};

	hsi2c@13920000 {
		#address-cells = <0x01>;
		#size-cells = <0x00>;
		clock-names = "rate_hsi2c\0gate_hsi2c";
		clocks = <0x10 0x15f 0x10 0x15f>;
		compatible = "samsung,exynos5-hsi2c";
		gpio_scl = <0x2c 0x02 0x01>;
		gpio_sda = <0x2c 0x01 0x01>;
		interrupts = <0x00 0x1cc 0x00>;
		pinctrl-0 = <0x3e>;
		pinctrl-names = "default";
		reg = <0x00 0x13920000 0x1000>;
		samsung,check-transdone-int;
		samsung,scl-clk-stretching;
		status = "disabled";
	};

	hsi2c@13930000 {
		#address-cells = <0x01>;
		#size-cells = <0x00>;
		clock-names = "rate_hsi2c\0gate_hsi2c";
		clocks = <0x10 0x160 0x10 0x160>;
		compatible = "samsung,exynos5-hsi2c";
		gpio_scl = <0x2c 0x05 0x01>;
		gpio_sda = <0x2c 0x04 0x01>;
		interrupts = <0x00 0x1cf 0x00>;
		pinctrl-0 = <0x3f>;
		pinctrl-names = "default";
		reg = <0x00 0x13930000 0x1000>;
		samsung,check-transdone-int;
		samsung,scl-clk-stretching;
		status = "disabled";
	};

	hsi2c@13940000 {
		#address-cells = <0x01>;
		#size-cells = <0x00>;
		clock-names = "rate_hsi2c\0gate_hsi2c";
		clocks = <0x10 0x160 0x10 0x160>;
		compatible = "samsung,exynos5-hsi2c";
		gpio_scl = <0x2c 0x07 0x01>;
		gpio_sda = <0x2c 0x06 0x01>;
		interrupts = <0x00 0x1d0 0x00>;
		pinctrl-0 = <0x40>;
		pinctrl-names = "default";
		reg = <0x00 0x13940000 0x1000>;
		samsung,check-transdone-int;
		samsung,scl-clk-stretching;
		status = "disabled";
	};

	hsi2c@13950000 {
		#address-cells = <0x01>;
		#size-cells = <0x00>;
		clock-frequency = <0x61a80>;
		clock-names = "rate_hsi2c\0gate_hsi2c";
		clocks = <0x10 0x14c 0x10 0x14c>;
		compatible = "samsung,exynos5-hsi2c";
		gpio_scl = <0x31 0x00 0x01>;
		gpio_sda = <0x31 0x01 0x01>;
		gpios = <0x31 0x01 0x00 0x31 0x00 0x00>;
		interrupts = <0x00 0x1c9 0x00>;
		pinctrl-0 = <0x30>;
		pinctrl-names = "default";
		reg = <0x00 0x13950000 0x1000>;
		samsung,check-transdone-int;
		samsung,scl-clk-stretching;
		status = "okay";
	};

	hsi2c@13960000 {
		#address-cells = <0x01>;
		#size-cells = <0x00>;
		clock-names = "rate_hsi2c\0gate_hsi2c";
		clocks = <0x10 0x14d 0x10 0x14d>;
		compatible = "samsung,exynos5-hsi2c";
		gpio_scl = <0x31 0x02 0x01>;
		gpio_sda = <0x31 0x03 0x01>;
		interrupts = <0x00 0x1ca 0x00>;
		pinctrl-0 = <0x32>;
		pinctrl-names = "default";
		reg = <0x00 0x13960000 0x1000>;
		samsung,check-transdone-int;
		samsung,scl-clk-stretching;
		status = "okay";

		sx9310-i2c@28 {
			compatible = "sx9310-i2c";
			interrupt-parent = <0x18>;
			interrupts = <0x04 0x00 0x00>;
			pinctrl-0 = <0x33>;
			pinctrl-names = "default";
			reg = <0x28>;
			status = "okay";
			sx9310-i2c,nirq-gpio = <0x18 0x04 0x00>;
			sx9310-i2c,normal_th = <0xa8>;
		};
	};

	i2c@13830000 {
		#address-cells = <0x01>;
		#size-cells = <0x00>;
		clock-names = "rate_i2c\0gate_i2c";
		clocks = <0x10 0x136 0x10 0x136>;
		compatible = "samsung,s3c2440-i2c";
		interrupts = <0x00 0x1a8 0x00>;
		pinctrl-0 = <0x1e>;
		pinctrl-names = "default";
		reg = <0x00 0x13830000 0x100>;
		samsung,i2c-max-bus-freq = <0x61a80>;
		status = "okay";

		pn547@2B {
			clkctrl-reg = <0x11c8600c>;
			compatible = "pn547";
			interrupt-parent = <0x18>;
			interrupts = <0x03 0x00 0x00>;
			pinctrl-0 = <0x23 0x24 0x25 0x26 0x27 0x28 0x29>;
			pinctrl-names = "default";
			pn547,firm-gpio = <0x1f 0x00 0x00>;
			pn547,irq-gpio = <0x18 0x03 0x00>;
			pn547,nfc_clkreq = <0x21 0x03 0x02>;
			pn547,nfc_clkreq_int = <0x22 0x06 0x00>;
			pn547,pvdd-gpio = <0x20 0x00 0x00>;
			reg = <0x2b>;
		};
	};

	i2c@13840000 {
		#address-cells = <0x01>;
		#size-cells = <0x00>;
		clock-names = "rate_i2c\0gate_i2c";
		clocks = <0x10 0x12e 0x10 0x12e>;
		compatible = "samsung,s3c2440-i2c";
		interrupts = <0x00 0x1a9 0x00>;
		pinctrl-0 = <0x1a>;
		pinctrl-names = "default";
		reg = <0x00 0x13840000 0x100>;
		samsung,i2c-max-bus-freq = <0x61a80>;
		samsung,i2c-sda-delay = <0x64>;
		status = "okay";

		touchscreen@20 {
			compatible = "zinitix,bt532_ts_device";
			pinctrl-0 = <0x1b>;
			pinctrl-1 = <0x1c>;
			pinctrl-names = "on_state\0off_state";
			reg = <0x20>;
			zinitix,afe_base = <0x100f>;
			zinitix,bringup = "true";
			zinitix,chip_name = "ZT7538";
			zinitix,firmware_name = "tsp_zinitix/zt7538_xcover4.fw";
			zinitix,gpio_ldo_en;
			zinitix,irq_gpio = <0x1d 0x02 0x00>;
			zinitix,mis_cal_check = "true";
			zinitix,orientation = <0x00>;
			zinitix,page_size = <0x80>;
			zinitix,pat_function = <0x02>;
			zinitix,project_name = "xcover4";
			zinitix,regulator_avdd = "tsp_avdd";
			zinitix,x_resolution = <0x2d0>;
			zinitix,y_resolution = <0x500>;
		};
	};

	i2c@13880000 {
		#address-cells = <0x01>;
		#size-cells = <0x00>;
		clock-names = "rate_i2c\0gate_i2c";
		clocks = <0x10 0x138 0x10 0x138>;
		compatible = "samsung,s3c2440-i2c";
		interrupts = <0x00 0x1ad 0x00>;
		pinctrl-0 = <0x16>;
		pinctrl-names = "default";
		reg = <0x00 0x13880000 0x100>;
		samsung,i2c-clk-logging;
		status = "okay";

		muic-universal@14 {
			compatible = "muic-universal";
			muic,undefined_range;
			muic-universal,chip_name = "sm,sm5504";
			muic-universal,irq-gpio = <0x18 0x01 0x00>;
			pinctrl-0 = <0x17>;
			pinctrl-names = "default";
			reg = <0x14>;
			status = "okay";
		};
	};

	i2c@13890000 {
		#address-cells = <0x01>;
		#size-cells = <0x00>;
		clock-names = "rate_i2c\0gate_i2c";
		clocks = <0x10 0x137 0x10 0x137>;
		compatible = "samsung,s3c2440-i2c";
		interrupts = <0x00 0x1ae 0x00>;
		pinctrl-0 = <0x19>;
		pinctrl-names = "default";
		reg = <0x00 0x13890000 0x100>;
		samsung,i2c-max-bus-freq = <0x61a80>;
		status = "okay";

		isl98611@29 {
			compatible = "i2c,isl98611";
			reg = <0x29>;
		};
	};

	i2c@138D0000 {
		#address-cells = <0x01>;
		#size-cells = <0x00>;
		clock-names = "rate_i2c\0gate_i2c";
		clocks = <0x10 0x12c 0x10 0x12c>;
		compatible = "samsung,s3c2440-i2c";
		interrupts = <0x00 0x1c5 0x00>;
		pinctrl-0 = <0x2a>;
		pinctrl-names = "default";
		reg = <0x00 0x138d0000 0x100>;
		samsung,i2c-max-bus-freq = <0x61a80>;
		samsung,i2c-sda-delay = <0x64>;
		status = "okay";

		ak09916c-i2c@0C {
			ak09916c-i2c,chip_pos = <0x07>;
			compatible = "ak09916c-i2c";
			reg = <0x0c>;
		};

		cm36686@60 {
			cm36686,cal_fail_adc = <0x19>;
			cm36686,cal_skip_adc = <0x09>;
			cm36686,cancel_hi_thd = <0x0f>;
			cm36686,cancel_low_thd = <0x0a>;
			cm36686,default_hi_thd = <0x15>;
			cm36686,default_low_thd = <0x0f>;
			cm36686,default_trim = <0x03>;
			cm36686,irq_gpio = <0x18 0x00 0x00>;
			cm36686,vdd_always_on = <0x01>;
			cm36686,vled_same_vdd = <0x01>;
			compatible = "cm36686";
			interrupt-parent = <0x18>;
			interrupts = <0x00 0x00 0x00>;
			pinctrl-0 = <0x2e>;
			pinctrl-names = "default";
			reg = <0x60>;
		};

		k2hh-i2c@1D {
			compatible = "k2hh-i2c";
			interrupt-parent = <0x2c>;
			interrupts = <0x02 0x00 0x00>;
			k2hh,axis_map_x = <0x00>;
			k2hh,axis_map_y = <0x01>;
			k2hh,axis_map_z = <0x02>;
			k2hh,irq_gpio = <0x2c 0x02 0x00>;
			k2hh,min_interval = <0x02>;
			k2hh,negate_x = <0x00>;
			k2hh,negate_y = <0x00>;
			k2hh,negate_z = <0x01>;
			k2hh,poll_interval = <0x64>;
			k2hh,vio-supply = <0x2d>;
			pinctrl-0 = <0x2b>;
			pinctrl-names = "default";
			reg = <0x1d>;
		};
	};

	i2c@138E0000 {
		#address-cells = <0x01>;
		#size-cells = <0x00>;
		clock-names = "rate_i2c\0gate_i2c";
		clocks = <0x10 0x12d 0x10 0x12d>;
		compatible = "samsung,s3c2440-i2c";
		interrupts = <0x00 0x1c6 0x00>;
		pinctrl-0 = <0x2f>;
		pinctrl-names = "default";
		reg = <0x00 0x138e0000 0x100>;
		status = "disabled";
	};

	i2s@148A0000 {
		clock-names = "iis\0i2s_opclk0\0i2s_opclk1";
		clocks = <0x10 0x2c7 0x10 0x2e5 0x10 0x2e5>;
		compatible = "samsung,i2s-v5";
		dma-names = "tx\0rx";
		dmas = <0x3c 0x1d 0x3c 0x1e>;
		interrupts = <0x00 0x45 0x00>;
		linux,phandle = <0x81>;
		phandle = <0x81>;
		reg = <0x00 0x148a0000 0x100>;
		samsung,amixer = <0x04>;
		samsung,i2s-str;
		samsung,lpass-subip;
		samsung,supports-esa-dma;
		samsung,supports-rstclr;
		samsung,supports-secdai;
		status = "okay";

		i2s-sec {
			clock-names = "iis\0i2s_opclk0\0i2s_opclk1";
			clocks = <0x10 0x2c7 0x10 0x2e5 0x10 0x2e5>;
			dma-names = "tx-sec";
			dmas = <0x3c 0x1c>;
		};
	};

	i2s@148B0000 {
		clock-names = "iis\0i2s_opclk0\0i2s_opclk1";
		clocks = <0x10 0x2c8 0x10 0x2e5 0x10 0x2e5>;
		compatible = "samsung,i2s-v5";
		dma-names = "rx";
		dmas = <0x3c 0x1f>;
		interrupts = <0x00 0x47 0x00>;
		linux,phandle = <0x85>;
		phandle = <0x85>;
		reg = <0x00 0x148b0000 0x100>;
		samsung,i2s-str;
		samsung,lpass-subip;
		samsung,supports-i2s-amp;
		samsung,supports-rstclr;
		status = "okay";
	};

	input_booster {
		#address-cells = <0x01>;
		#size-cells = <0x00>;
		compatible = "input_booster";
		status = "okay";

		booster_key@1 {
			input_booster,cpu_freqs = <0x137090>;
			input_booster,head_times = <0x1f4>;
			input_booster,hmp_boost = <0x00>;
			input_booster,int_freqs = <0x00>;
			input_booster,kfc_freqs = <0x137090>;
			input_booster,label = "KEY";
			input_booster,levels = <0x01>;
			input_booster,mif_freqs = <0x00>;
			input_booster,phase_times = <0x00>;
			input_booster,tail_times = <0x1f4>;
			input_booster,type = <0x00>;
		};

		booster_key@2 {
			input_booster,cpu_freqs = <0x137090>;
			input_booster,head_times = <0x00>;
			input_booster,hmp_boost = <0x00>;
			input_booster,int_freqs = <0x00>;
			input_booster,kfc_freqs = <0x137090>;
			input_booster,label = "TOUCHKEY";
			input_booster,levels = <0x01>;
			input_booster,mif_freqs = <0x00>;
			input_booster,phase_times = <0x00>;
			input_booster,tail_times = <0x12c>;
			input_booster,type = <0x01>;
		};

		booster_key@3 {
			input_booster,cpu_freqs = <0x137090 0x137090 0xeadd0>;
			input_booster,head_times = <0xc8 0xc8 0x00>;
			input_booster,hmp_boost = <0x00 0x00 0x00>;
			input_booster,int_freqs = <0x00 0x00 0x00>;
			input_booster,kfc_freqs = <0x137090 0x137090 0xeadd0>;
			input_booster,label = "TOUCH";
			input_booster,levels = <0x01 0x02 0x03>;
			input_booster,mif_freqs = <0x00 0x00 0x00>;
			input_booster,phase_times = <0x00 0x00 0x00>;
			input_booster,tail_times = <0x00 0x00 0x12c>;
			input_booster,type = <0x02>;
		};

		booster_key@4 {
			input_booster,cpu_freqs = <0x1506d0 0xfde80>;
			input_booster,head_times = <0x3e8 0x00>;
			input_booster,hmp_boost = <0x00 0x00>;
			input_booster,int_freqs = <0x00 0x00>;
			input_booster,kfc_freqs = <0x1506d0 0xfde80>;
			input_booster,label = "MULTITOUCH";
			input_booster,levels = <0x01 0x02>;
			input_booster,mif_freqs = <0x00 0x00>;
			input_booster,phase_times = <0x00 0x00>;
			input_booster,tail_times = <0x00 0x1f4>;
			input_booster,type = <0x03>;
		};

		booster_key@5 {
			input_booster,cpu_freqs = <0x137090 0x137090>;
			input_booster,head_times = <0xc8 0xc8>;
			input_booster,hmp_boost = <0x00 0x00>;
			input_booster,int_freqs = <0x00 0x00>;
			input_booster,kfc_freqs = <0x137090 0x137090>;
			input_booster,label = "KEYBOARD";
			input_booster,levels = <0x01 0x02>;
			input_booster,mif_freqs = <0x00 0x00>;
			input_booster,phase_times = <0x00 0x00>;
			input_booster,tail_times = <0x00 0x00>;
			input_booster,type = <0x04>;
		};

		booster_key@6 {
			input_booster,cpu_freqs = <0x137090 0xeadd0>;
			input_booster,head_times = <0xc8 0x00>;
			input_booster,hmp_boost = <0x00 0x00>;
			input_booster,int_freqs = <0x00 0x00>;
			input_booster,kfc_freqs = <0x137090 0xeadd0>;
			input_booster,label = "MOUSE";
			input_booster,levels = <0x01 0x02>;
			input_booster,mif_freqs = <0x00 0x00>;
			input_booster,phase_times = <0x00 0x00>;
			input_booster,tail_times = <0x00 0x12c>;
			input_booster,type = <0x05>;
		};

		booster_key@7 {
			input_booster,cpu_freqs = <0x137090 0x00>;
			input_booster,head_times = <0xc8 0x00>;
			input_booster,hmp_boost = <0x00 0x00>;
			input_booster,int_freqs = <0x00 0x00>;
			input_booster,kfc_freqs = <0x137090 0x00>;
			input_booster,label = "MOUSE WHEEL";
			input_booster,levels = <0x01 0x02>;
			input_booster,mif_freqs = <0x00 0x00>;
			input_booster,phase_times = <0x00 0x00>;
			input_booster,tail_times = <0x00 0x00>;
			input_booster,type = <0x06>;
		};

		booster_key@8 {
			input_booster,cpu_freqs = <0x137090 0xeadd0>;
			input_booster,head_times = <0xc8 0x00>;
			input_booster,hmp_boost = <0x00 0x00>;
			input_booster,int_freqs = <0x00 0x00>;
			input_booster,kfc_freqs = <0x137090 0xeadd0>;
			input_booster,label = "PEN & HOVER";
			input_booster,levels = <0x01 0x02>;
			input_booster,mif_freqs = <0x00 0x00>;
			input_booster,phase_times = <0x00 0x00>;
			input_booster,tail_times = <0x00 0x12c>;
			input_booster,type = <0x07>;
		};

		booster_key@9 {
			input_booster,cpu_freqs = <0x1506d0 0xca648>;
			input_booster,head_times = <0xc8 0x00>;
			input_booster,hmp_boost = <0x00 0x00>;
			input_booster,int_freqs = <0x00 0x00>;
			input_booster,kfc_freqs = <0x1506d0 0xca648>;
			input_booster,label = "GAMEPAD";
			input_booster,levels = <0x01 0x02>;
			input_booster,mif_freqs = <0x00 0x00>;
			input_booster,phase_times = <0x00 0x00>;
			input_booster,tail_times = <0x00 0x12c>;
			input_booster,type = <0x08>;
		};
	};

	interrupt-controller@104E1000 {
		#address-cells = <0x00>;
		#interrupt-cells = <0x03>;
		compatible = "arm,cortex-a15-gic\0arm,cortex-a9-gic";
		interrupt-controller;
		interrupts = <0x01 0x09 0xf04>;
		linux,phandle = <0x01>;
		phandle = <0x01>;
		reg = <0x00 0x104e1000 0x1000 0x00 0x104e2000 0x1000 0x00 0x104e4000 0x2000 0x00 0x104e6000 0x2000>;
	};

	iommu-domain_disp {
		#address-cells = <0x02>;
		#size-cells = <0x01>;
		compatible = "samsung,exynos-iommu-bus";
		domain-clients = <0x69>;
		ranges;

		sysmmu@14860000 {
			clock-names = "aclk";
			clocks = <0x10 0x44d>;
			compatible = "samsung,exynos7420-sysmmu";
			interrupts = <0x00 0xc0 0x00 0x00 0xc1 0x00>;
			master_ip_list = <0x69>;
			qos = <0x0f>;
			reg = <0x00 0x14860000 0x3000>;
			samsung,power-domain = <0x0a>;
			sysmmu,handle_secure-irq;
			sysmmu,secure_reg = <0x14850000>;
			sysmmu,v7tlb_property = <0x00 0x00 0x02 0x00 0x04 0x00 0x05 0x00>;
		};
	};

	iommu-domain_mfc_mscl {
		#address-cells = <0x02>;
		#size-cells = <0x01>;
		compatible = "samsung,exynos-iommu-bus";
		domain-clients = <0x63 0x64 0x65 0x66 0x67 0x68>;
		ranges;

		scaler@12C10000 {
			clock-names = "gate";
			clocks = <0x10 0x262>;
			compatible = "samsung,exynos5-scaler";
			interrupts = <0x00 0x191 0x00>;
			linux,phandle = <0x64>;
			phandle = <0x64>;
			prefetch-buffer,disable;
			reg = <0x00 0x12c10000 0x1300>;
			samsung,power-domain = <0x09>;
		};

		smfc@12C20000 {
			clock-names = "gate";
			clocks = <0x10 0x263>;
			compatible = "samsung,exynos8890-jpeg";
			interrupts = <0x00 0x194 0x00>;
			linux,phandle = <0x63>;
			phandle = <0x63>;
			reg = <0x00 0x12c20000 0x2000>;
			samsung,power-domain = <0x09>;
		};

		sysmmu@0x14470000 {
			clock-names = "aclk";
			clocks = <0x10 0x44e>;
			compatible = "samsung,exynos7420-sysmmu";
			interrupts = <0x00 0x80 0x00>;
			master_ip_list = <0x66 0x67 0x68>;
			qos = <0x0f>;
			reg = <0x00 0x14470000 0x3000>;
			samsung,power-domain = <0x0b>;
			sysmmu,v7tlb_property = <0x8000 0x0a 0x8004 0x0a 0x01 0x0a 0x8001 0x0a 0x8005 0x0a 0x8002 0x0a 0x8006 0x0a 0x800a 0x0a 0x8003 0x0a 0x03 0x20>;
		};

		sysmmu@12C80000 {
			clock-names = "aclk";
			clocks = <0x10 0x44c>;
			compatible = "samsung,exynos7420-sysmmu";
			interrupts = <0x00 0x160 0x00 0x00 0x199 0x00>;
			master_ip_list = <0x63 0x64 0x65 0x66>;
			reg = <0x00 0x12c80000 0x3000>;
			samsung,power-domain = <0x09>;
			sysmmu,handle_secure-irq;
			sysmmu,secure_reg = <0x12c70000>;
			sysmmu,v7tlb_property = <0x02 0x4a 0x06 0x4a 0x0e 0x46 0x8022 0x46 0x8026 0x46 0x802a 0x46>;
		};
	};

	ion {
		compatible = "samsung,exynos5430-ion";
	};

	lpass@148F0000 {
		clock-names = "fout_aud_pll\0dout_sclk_mi2s\0dispaud_decon";
		clocks = <0x10 0x2e4 0x10 0x2c7 0x10 0x2bf>;
		compatible = "samsung,exynos7570-lpass";
		reg = <0x00 0x148f0000 0x1040>;
		samsung,power-domain = <0x38>;
		samsung,syscon-phandle = <0x0e>;
		status = "okay";
	};

	mali@11400000 {
		clock-names = "vclk_g3d";
		clocks = <0x10 0xcb>;
		compatible = "arm,mali";
		interrupt-names = "JOB\0MMU\0GPU";
		interrupts = <0x00 0x11a 0x00 0x00 0x11b 0x00 0x00 0x119 0x00>;
		reg = <0x00 0x11400000 0x5000>;
		samsung,power-domain = <0x0c>;
	};

	mct@101B0000 {
		#interrupt-cells = <0x01>;
		clock-names = "fin_pll\0mct";
		clocks = <0x10 0x01 0x10 0x172>;
		compatible = "samsung,exynos4210-mct";
		interrupt-controller;
		interrupt-parent = <0x0f>;
		interrupts = <0x00 0x01 0x02 0x03 0x04 0x05 0x06 0x07 0x08 0x09 0x0a 0x0b>;
		reg = <0x00 0x101b0000 0x800>;
		use-clockevent-only;

		mct-map {
			#address-cells = <0x00>;
			#interrupt-cells = <0x01>;
			#size-cells = <0x00>;
			interrupt-map = <0x00 0x01 0x00 0x66 0x00 0x01 0x01 0x00 0x67 0x00 0x02 0x01 0x00 0x68 0x00 0x03 0x01 0x00 0x69 0x00 0x04 0x01 0x00 0x6a 0x00 0x05 0x01 0x00 0x6b 0x00 0x06 0x01 0x00 0x6c 0x00 0x07 0x01 0x00 0x6d 0x00 0x08 0x01 0x00 0x6e 0x00 0x09 0x01 0x00 0x6f 0x00 0x0a 0x01 0x00 0x70 0x00 0x0b 0x01 0x00 0x71 0x00>;
			linux,phandle = <0x0f>;
			phandle = <0x0f>;
		};
	};

	mcu_ipc@10500000 {
		compatible = "samsung,exynos-shd-ipc-mailbox";
		interrupts = <0x00 0x171 0x00>;
		mcu,id = <0x00>;
		mcu,irq_affinity_mask = <0x03>;
		mcu,name = "mcu_ipc_cp";
		reg = <0x00 0x10500000 0x180>;
	};

	mcu_ipc@10570000 {
		compatible = "samsung,exynos-shd-ipc-mailbox";
		interrupts = <0x00 0x175 0x00>;
		mcu,id = <0x01>;
		mcu,name = "mcu_ipc_gnss";
		reg = <0x00 0x10570000 0x180>;
	};

	mdev_output {
		compatible = "samsung,exynos5-mdev";
	};

	memory@40000000 {
		device_type = "memory";
		reg = <0x00 0x40000000 0x3e800000>;
	};

	memory@80000000 {
		device_type = "memory";
		reg = <0x00 0x80000000 0x40000000>;
	};

	mfc0@12C30000 {
		#pb-id-cells = <0x00>;
		clock-names = "aclk_mfc";
		clock_rate = <0x18bc65c0>;
		clocks = <0x10 0x264>;
		compatible = "samsung,mfc-v6";
		interrupts = <0x00 0x162 0x00>;
		ip_ver = <0x11>;
		linux,phandle = <0x65>;
		min_rate = <0x186a0>;
		num_qos_steps = <0x02>;
		phandle = <0x65>;
		reg = <0x00 0x12c30000 0x10000>;
		samsung,power-domain = <0x09>;
		status = "ok";

		mfc_qos_table {

			mfc_qos_variant_0 {
				freq_cpu = <0x00>;
				freq_int = <0x65518>;
				freq_kfc = <0x00>;
				freq_mfc = <0x00>;
				freq_mif = <0x65518>;
				has_enc_table = <0x00>;
				thrd_mb = <0x00>;
			};

			mfc_qos_variant_1 {
				freq_cpu = <0x00>;
				freq_int = <0x65518>;
				freq_kfc = <0x00>;
				freq_mfc = <0x00>;
				freq_mif = <0xa2990>;
				has_enc_table = <0x00>;
				thrd_mb = <0x3bc40>;
			};
		};
	};

	mif_pdata {
		compatible = "sec_modem,modem_pdata";
		gpios = <0x1f 0x02 0x00 0x1f 0x03 0x00 0x1f 0x04 0x00>;
		interrupts = <0x00 0x12 0x00 0x00 0x1df 0x00>;
		mbx_ap2cp_cp_voltage_700 = <0x05>;
		mbx_ap2cp_cp_voltage_830 = <0x07>;
		mbx_ap2cp_msg = <0x00>;
		mbx_ap2cp_united_status = <0x02>;
		mbx_cp2ap_dvfsreq = <0x04>;
		mbx_cp2ap_dvfsreq_mif = <0x06>;
		mbx_cp2ap_msg = <0x01>;
		mbx_cp2ap_united_status = <0x03>;
		mif,int_ap2cp_active = <0x03>;
		mif,int_ap2cp_msg = <0x00>;
		mif,int_ap2cp_status = <0x02>;
		mif,ipc_version = <0x32>;
		mif,irq_cp2ap_active = <0x03>;
		mif,irq_cp2ap_msg = <0x00>;
		mif,irq_cp2ap_perf_req_mif = <0x06>;
		mif,irq_cp2ap_status = <0x02>;
		mif,irq_cp2ap_wake_lock = <0x08>;
		mif,link_attrs = <0x7c8>;
		mif,link_name = "shmem";
		mif,link_types = <0x200>;
		mif,modem_net = <0x00>;
		mif,modem_type = <0x0a>;
		mif,name = "ss305ap";
		mif,num_iodevs = <0x13>;
		mif,use_handover = <0x00>;
		pinctrl-0 = <0x7e 0x7f>;
		pinctrl-names = "default";
		reg = <0x00 0x10000 0x00>;
		sbi_ap_status_mask = <0x0f>;
		sbi_ap_status_pos = <0x01>;
		sbi_cp_cpu_freq_asv_mask = <0x07>;
		sbi_cp_cpu_freq_asv_pos = <0x13>;
		sbi_cp_status_mask = <0x0f>;
		sbi_cp_status_pos = <0x01>;
		sbi_ds_det_mask = <0x03>;
		sbi_ds_det_pos = <0x0e>;
		sbi_evs_mode_mask = <0x01>;
		sbi_evs_mode_pos = <0x07>;
		sbi_lte_active_mask = <0x01>;
		sbi_lte_active_pos = <0x05>;
		sbi_pda_active_mask = <0x01>;
		sbi_pda_active_pos = <0x05>;
		sbi_sys_rev_mask = <0xff>;
		sbi_sys_rev_pos = <0x06>;
		status = "okay";

		iodevs {

			io_device_0 {
				iod,app = "RIL";
				iod,attrs = <0x02>;
				iod,format = <0x00>;
				iod,id = <0xeb>;
				iod,io_type = <0x00>;
				iod,links = <0x200>;
				iod,name = "umts_ipc0";
			};

			io_device_1 {
				iod,app = "RIL";
				iod,attrs = <0x02>;
				iod,format = <0x00>;
				iod,id = <0xec>;
				iod,io_type = <0x00>;
				iod,links = <0x200>;
				iod,name = "umts_ipc1";
			};

			io_device_10 {
				iod,attrs = <0x02>;
				iod,format = <0x01>;
				iod,id = <0x0e>;
				iod,io_type = <0x01>;
				iod,links = <0x200>;
				iod,name = "rmnet4";
			};

			io_device_11 {
				iod,attrs = <0x02>;
				iod,format = <0x01>;
				iod,id = <0x0f>;
				iod,io_type = <0x01>;
				iod,links = <0x200>;
				iod,name = "rmnet5";
			};

			io_device_12 {
				iod,attrs = <0x02>;
				iod,format = <0x01>;
				iod,id = <0x10>;
				iod,io_type = <0x01>;
				iod,links = <0x200>;
				iod,name = "rmnet6";
			};

			io_device_13 {
				iod,attrs = <0x02>;
				iod,format = <0x01>;
				iod,id = <0x11>;
				iod,io_type = <0x01>;
				iod,links = <0x200>;
				iod,name = "rmnet7";
			};

			io_device_14 {
				iod,app = "RIL";
				iod,attrs = <0x02>;
				iod,format = <0x03>;
				iod,id = <0x00>;
				iod,io_type = <0x02>;
				iod,links = <0x200>;
				iod,name = "multipdp";
			};

			io_device_15 {
				iod,app = "CBD";
				iod,attrs = <0x02>;
				iod,format = <0x04>;
				iod,id = <0xd7>;
				iod,io_type = <0x00>;
				iod,links = <0x200>;
				iod,name = "umts_boot0";
			};

			io_device_16 {
				iod,app = "CBD";
				iod,attrs = <0x202>;
				iod,format = <0x05>;
				iod,id = <0xe1>;
				iod,io_type = <0x00>;
				iod,links = <0x200>;
				iod,name = "umts_ramdump0";
			};

			io_device_17 {
				iod,attrs = <0x802>;
				iod,format = <0x01>;
				iod,id = <0x21>;
				iod,io_type = <0x00>;
				iod,links = <0x200>;
				iod,name = "smd4";
				iod,option_region = "kor_skt";
			};

			io_device_18 {
				iod,attrs = <0x802>;
				iod,format = <0x01>;
				iod,id = <0x1a>;
				iod,io_type = <0x00>;
				iod,links = <0x200>;
				iod,name = "umts_ciq0";
				iod,option_region = "usa_att";
			};

			io_device_2 {
				iod,app = "RFS";
				iod,attrs = <0x02>;
				iod,format = <0x02>;
				iod,id = <0xf5>;
				iod,io_type = <0x00>;
				iod,links = <0x200>;
				iod,name = "umts_rfs0";
			};

			io_device_3 {
				iod,app = "CSVT";
				iod,attrs = <0x02>;
				iod,format = <0x01>;
				iod,id = <0x01>;
				iod,io_type = <0x00>;
				iod,links = <0x200>;
				iod,name = "umts_csd";
			};

			io_device_4 {
				iod,app = "Data Router";
				iod,attrs = <0x02>;
				iod,format = <0x01>;
				iod,id = <0x19>;
				iod,io_type = <0x00>;
				iod,links = <0x200>;
				iod,max_tx_size = <0x800>;
				iod,name = "umts_router";
			};

			io_device_5 {
				iod,app = "DIAG";
				iod,attrs = <0x02>;
				iod,format = <0x01>;
				iod,id = <0x1c>;
				iod,io_type = <0x00>;
				iod,links = <0x200>;
				iod,name = "umts_dm0";
			};

			io_device_6 {
				iod,app = "NET";
				iod,attrs = <0x02>;
				iod,format = <0x01>;
				iod,id = <0x0a>;
				iod,io_type = <0x01>;
				iod,links = <0x200>;
				iod,name = "rmnet0";
			};

			io_device_7 {
				iod,app = "NET";
				iod,attrs = <0x02>;
				iod,format = <0x01>;
				iod,id = <0x0b>;
				iod,io_type = <0x01>;
				iod,links = <0x200>;
				iod,name = "rmnet1";
			};

			io_device_8 {
				iod,app = "NET";
				iod,attrs = <0x02>;
				iod,format = <0x01>;
				iod,id = <0x0c>;
				iod,io_type = <0x01>;
				iod,links = <0x200>;
				iod,name = "rmnet2";
			};

			io_device_9 {
				iod,app = "NET";
				iod,attrs = <0x02>;
				iod,format = <0x01>;
				iod,id = <0x0d>;
				iod,io_type = <0x01>;
				iod,links = <0x200>;
				iod,name = "rmnet3";
			};
		};
	};

	muic {
		muic,support-list = "+OTG:GND\0-MHL:1K\0-VZW Accessory:28.7K\0-VZW Incompatible:34K\0-Smartdock:40.2K\0-HMT:49.9K\0-Audiodock:64.9K\0-USB LANHUB:80.07K\0-Charging Cable:102K\0-Universal Multimedia dock:121K\0+Jig USB Off:255K\0+Jig USB On:301K\0-Deskdock:365K\0-TYPE2 Charger:442K\0+Jig UART Off:523K\0+Jig UART On:619K\0+TA:OPEN\0+USB:OPEN\0+CDP:OPEN\0-Undefined Charging:XXX";
		status = "okay";
	};

	pd-dispaud@11C84020 {
		cal_id = <0xb138000d>;
		check-cp-status = "true";
		compatible = "samsung,exynos-pd";
		linux,phandle = <0x0a>;
		phandle = <0x0a>;
		reg = <0x00 0x11c84020 0x20>;
		status = "okay";

		spd-aud@11C84020 {
			compatible = "samsung,exynos-spd";
			linux,phandle = <0x38>;
			phandle = <0x38>;
		};

		spd-disp@11C84020 {
			compatible = "samsung,exynos-spd";
			linux,phandle = <0x5e>;
			phandle = <0x5e>;
		};

		spd-fm@11C84020 {
			compatible = "samsung,exynos-spd";
			linux,phandle = <0x6f>;
			phandle = <0x6f>;
		};
	};

	pd-g3d@11C84000 {
		cal_id = <0xb1380000>;
		compatible = "samsung,exynos-pd";
		linux,phandle = <0x0c>;
		phandle = <0x0c>;
		reg = <0x00 0x11c84000 0x20>;
		status = "okay";
	};

	pd-isp@11C84040 {
		cal_id = <0xb1380003>;
		compatible = "samsung,exynos-pd";
		devfreq-sync-voltage = <0x03>;
		linux,phandle = <0x0b>;
		parent = <0x09>;
		phandle = <0x0b>;
		reg = <0x00 0x11c84040 0x20>;
		status = "okay";
	};

	pd-mfcmscl@11C84060 {
		cal_id = <0xb1380008>;
		compatible = "samsung,exynos-pd";
		linux,phandle = <0x09>;
		phandle = <0x09>;
		reg = <0x00 0x11c84060 0x20>;
		status = "okay";
	};

	phy_m4s4_dsi@148F100C {
		#phy-cells = <0x01>;
		compatible = "samsung,mipi-phy-dsim";
		isolation = <0x70c>;
		linux,phandle = <0x5f>;
		phandle = <0x5f>;
		reg = <0x00 0x148f100c 0x04>;
		reset = <0x00>;
		samsung,pmu-syscon = <0x0e>;
	};

	phy_phy_csis@144F1040 {
		#phy-cells = <0x01>;
		compatible = "samsung,mipi-phy-csis";
		isolation = <0x70c 0x714>;
		linux,phandle = <0x6e>;
		phandle = <0x6e>;
		reg = <0x00 0x144f1040 0x04>;
		reset = <0x01 0x00>;
		samsung,pmu-syscon = <0x0e>;
	};

	pinctrl@10530000 {
		compatible = "samsung,exynos7570-pinctrl";
		interrupts = <0x00 0x188 0x00>;
		reg = <0x00 0x10530000 0x1000>;

		gpm0 {
			#gpio-cells = <0x02>;
			#interrupt-cells = <0x02>;
			gpio-controller;
			interrupt-controller;
		};

		speedy-bus {
			linux,phandle = <0x41>;
			phandle = <0x41>;
			samsung,pin-con-pdn = <0x03>;
			samsung,pin-drv = <0x00>;
			samsung,pin-function = <0x02>;
			samsung,pins = "gpm0-0";
		};
	};

	pinctrl@13750000 {
		compatible = "samsung,exynos7570-pinctrl";
		interrupts = <0x00 0xfa 0x00>;
		pinctrl-0 = <0x04>;
		pinctrl-names = "sleep";
		reg = <0x00 0x13750000 0x1000>;

		gpr0 {
			#gpio-cells = <0x02>;
			#interrupt-cells = <0x02>;
			gpio-controller;
			interrupt-controller;
		};

		gpr1 {
			#gpio-cells = <0x02>;
			#interrupt-cells = <0x02>;
			gpio-controller;
			interrupt-controller;
		};

		gpr4 {
			#gpio-cells = <0x02>;
			#interrupt-cells = <0x02>;
			gpio-controller;
			interrupt-controller;
		};

		sd0-bus-width1 {
			linux,phandle = <0x4e>;
			phandle = <0x4e>;
			samsung,pin-drv = <0x02>;
			samsung,pin-function = <0x02>;
			samsung,pin-pud = <0x03>;
			samsung,pins = "gpr1-0";
		};

		sd0-bus-width4 {
			linux,phandle = <0x4f>;
			phandle = <0x4f>;
			samsung,pin-drv = <0x02>;
			samsung,pin-function = <0x02>;
			samsung,pin-pud = <0x03>;
			samsung,pins = "gpr1-1\0gpr1-2\0gpr1-3";
		};

		sd0-bus-width8 {
			linux,phandle = <0x50>;
			phandle = <0x50>;
			samsung,pin-drv = <0x02>;
			samsung,pin-function = <0x02>;
			samsung,pin-pud = <0x03>;
			samsung,pins = "gpr1-4\0gpr1-5\0gpr1-6\0gpr1-7";
		};

		sd0-clk {
			linux,phandle = <0x4b>;
			phandle = <0x4b>;
			samsung,pin-drv = <0x02>;
			samsung,pin-function = <0x02>;
			samsung,pin-pud = <0x00>;
			samsung,pins = "gpr0-0";
		};

		sd0-clk_fast_slew_rate_1x {
			linux,phandle = <0x51>;
			phandle = <0x51>;
			samsung,pin-drv = <0x00>;
			samsung,pin-function = <0x02>;
			samsung,pin-pud = <0x00>;
			samsung,pins = "gpr0-0";
		};

		sd0-clk_fast_slew_rate_2x {
			linux,phandle = <0x52>;
			phandle = <0x52>;
			samsung,pin-drv = <0x01>;
			samsung,pin-function = <0x02>;
			samsung,pin-pud = <0x00>;
			samsung,pins = "gpr0-0";
		};

		sd0-clk_fast_slew_rate_3x {
			linux,phandle = <0x53>;
			phandle = <0x53>;
			samsung,pin-drv = <0x02>;
			samsung,pin-function = <0x02>;
			samsung,pin-pud = <0x00>;
			samsung,pins = "gpr0-0";
		};

		sd0-clk_fast_slew_rate_4x {
			linux,phandle = <0x54>;
			phandle = <0x54>;
			samsung,pin-drv = <0x03>;
			samsung,pin-function = <0x02>;
			samsung,pin-pud = <0x00>;
			samsung,pins = "gpr0-0";
		};

		sd0-cmd {
			linux,phandle = <0x4c>;
			phandle = <0x4c>;
			samsung,pin-drv = <0x02>;
			samsung,pin-function = <0x02>;
			samsung,pin-pud = <0x03>;
			samsung,pins = "gpr0-1";
		};

		sd0-rdqs {
			linux,phandle = <0x4d>;
			phandle = <0x4d>;
			samsung,pin-drv = <0x02>;
			samsung,pin-function = <0x02>;
			samsung,pin-pud = <0x01>;
			samsung,pins = "gpr0-2";
		};

		sd2-bus-width1 {
			linux,phandle = <0x57>;
			phandle = <0x57>;
			samsung,pin-drv = <0x02>;
			samsung,pin-function = <0x02>;
			samsung,pin-pud = <0x03>;
			samsung,pins = "gpr4-2";
		};

		sd2-bus-width4 {
			linux,phandle = <0x58>;
			phandle = <0x58>;
			samsung,pin-drv = <0x02>;
			samsung,pin-function = <0x02>;
			samsung,pin-pud = <0x03>;
			samsung,pins = "gpr4-3\0gpr4-4\0gpr4-5";
		};

		sd2-clk {
			linux,phandle = <0x55>;
			phandle = <0x55>;
			samsung,pin-drv = <0x02>;
			samsung,pin-function = <0x02>;
			samsung,pin-pud = <0x00>;
			samsung,pins = "gpr4-0";
		};

		sd2-clk_fast_slew_rate_1x {
			linux,phandle = <0x5a>;
			phandle = <0x5a>;
			samsung,pin-drv = <0x00>;
			samsung,pin-function = <0x02>;
			samsung,pin-pud = <0x00>;
			samsung,pins = "gpr4-0";
		};

		sd2-clk_fast_slew_rate_2x {
			linux,phandle = <0x5b>;
			phandle = <0x5b>;
			samsung,pin-drv = <0x01>;
			samsung,pin-function = <0x02>;
			samsung,pin-pud = <0x00>;
			samsung,pins = "gpr4-0";
		};

		sd2-clk_fast_slew_rate_3x {
			linux,phandle = <0x5c>;
			phandle = <0x5c>;
			samsung,pin-drv = <0x02>;
			samsung,pin-function = <0x02>;
			samsung,pin-pud = <0x00>;
			samsung,pins = "gpr4-0";
		};

		sd2-clk_fast_slew_rate_4x {
			linux,phandle = <0x5d>;
			phandle = <0x5d>;
			samsung,pin-drv = <0x03>;
			samsung,pin-function = <0x02>;
			samsung,pin-pud = <0x00>;
			samsung,pins = "gpr4-0";
		};

		sd2-cmd {
			linux,phandle = <0x56>;
			phandle = <0x56>;
			samsung,pin-drv = <0x02>;
			samsung,pin-function = <0x02>;
			samsung,pin-pud = <0x03>;
			samsung,pins = "gpr4-1";
		};

		sleep-state {
			linux,phandle = <0x04>;
			phandle = <0x04>;

			gpr0-1 {
				samsung,pin-con-pdn = <0x02>;
				samsung,pin-pud-pdn = <0x00>;
				samsung,pins = "gpr0-1";
			};
		};
	};

	pinctrl@139B0000 {
		compatible = "samsung,exynos7570-pinctrl";
		interrupts = <0x00 0x1b6 0x00>;
		pinctrl-0 = <0x06>;
		pinctrl-1 = <0x07>;
		pinctrl-names = "default\0sleep";
		reg = <0x00 0x139b0000 0x1000>;

		decon_te_off {
			samsung,pin-function = <0x00>;
			samsung,pins = "gpe0-2";
		};

		decon_te_on {
			samsung,pin-function = <0x02>;
			samsung,pins = "gpe0-2";
		};

		ds_det {
			linux,phandle = <0x7f>;
			phandle = <0x7f>;
			samsung,pin-con-pdn = <0x03>;
			samsung,pin-function = <0x00>;
			samsung,pin-pud = <0x00>;
			samsung,pin-pud-pdn = <0x00>;
			samsung,pins = "gpd1-5";
		};

		ese_pvdd_en {
			samsung,pin-function = <0x01>;
			samsung,pin-pud = <0x01>;
			samsung,pin-val = <0x00>;
			samsung,pins = "gpf1-1";
		};

		fimc_is_mclk0_fn {
			linux,phandle = <0x7d>;
			phandle = <0x7d>;
			samsung,pin-drv = <0x01>;
			samsung,pin-function = <0x02>;
			samsung,pin-pud = <0x00>;
			samsung,pins = "gpe0-0";
		};

		fimc_is_mclk0_in {
			linux,phandle = <0x7b>;
			phandle = <0x7b>;
			samsung,pin-drv = <0x00>;
			samsung,pin-function = <0x00>;
			samsung,pin-pud = <0x00>;
			samsung,pins = "gpe0-0";
		};

		fimc_is_mclk0_out {
			samsung,pin-drv = <0x02>;
			samsung,pin-function = <0x01>;
			samsung,pin-pud = <0x01>;
			samsung,pins = "gpe0-0";
		};

		gpc0 {
			#gpio-cells = <0x02>;
			#interrupt-cells = <0x02>;
			gpio-controller;
			interrupt-controller;
			linux,phandle = <0x72>;
			phandle = <0x72>;
		};

		gpc1 {
			#gpio-cells = <0x02>;
			#interrupt-cells = <0x02>;
			gpio-controller;
			interrupt-controller;
		};

		gpc4 {
			#gpio-cells = <0x02>;
			#interrupt-cells = <0x02>;
			gpio-controller;
			interrupt-controller;
		};

		gpd1 {
			#gpio-cells = <0x02>;
			#interrupt-cells = <0x02>;
			gpio-controller;
			interrupt-controller;
			linux,phandle = <0x1f>;
			phandle = <0x1f>;
		};

		gpe0 {
			#gpio-cells = <0x02>;
			#interrupt-cells = <0x02>;
			gpio-controller;
			interrupt-controller;
		};

		gpf0 {
			#gpio-cells = <0x02>;
			#interrupt-cells = <0x02>;
			gpio-controller;
			interrupt-controller;
			linux,phandle = <0x35>;
			phandle = <0x35>;
		};

		gpf1 {
			#gpio-cells = <0x02>;
			#interrupt-cells = <0x02>;
			gpio-controller;
			interrupt-controller;
			linux,phandle = <0x20>;
			phandle = <0x20>;
		};

		gpf3 {
			#gpio-cells = <0x02>;
			#interrupt-cells = <0x02>;
			gpio-controller;
			interrupt-controller;
			linux,phandle = <0x31>;
			phandle = <0x31>;
		};

		hs-i2c0-bus {
			samsung,pin-con-pdn = <0x03>;
			samsung,pin-drv = <0x00>;
			samsung,pin-function = <0x03>;
			samsung,pin-pud = <0x03>;
			samsung,pins = "gpf3-0\0gpf3-1";
		};

		hs-i2c1-bus {
			linux,phandle = <0x32>;
			phandle = <0x32>;
			samsung,pin-con-pdn = <0x03>;
			samsung,pin-drv = <0x00>;
			samsung,pin-function = <0x03>;
			samsung,pin-pud = <0x03>;
			samsung,pins = "gpf3-2\0gpf3-3";
		};

		hs-i2c2-bus {
			linux,phandle = <0x34>;
			phandle = <0x34>;
			samsung,pin-con-pdn = <0x03>;
			samsung,pin-drv = <0x00>;
			samsung,pin-function = <0x02>;
			samsung,pin-pud = <0x00>;
			samsung,pins = "gpf0-1\0gpf0-0";
		};

		hs-i2c3-bus {
			linux,phandle = <0x36>;
			phandle = <0x36>;
			samsung,pin-con-pdn = <0x03>;
			samsung,pin-drv = <0x00>;
			samsung,pin-function = <0x02>;
			samsung,pin-pud = <0x00>;
			samsung,pins = "gpf0-3\0gpf0-2";
		};

		hs-i2c4-bus {
			linux,phandle = <0x37>;
			phandle = <0x37>;
			samsung,pin-con-pdn = <0x03>;
			samsung,pin-drv = <0x00>;
			samsung,pin-function = <0x02>;
			samsung,pin-pud = <0x03>;
			samsung,pins = "gpf1-1\0gpf1-0";
		};

		i2c1-bus {
			linux,phandle = <0x16>;
			phandle = <0x16>;
			samsung,pin-drv = <0x00>;
			samsung,pin-function = <0x02>;
			samsung,pin-pud = <0x03>;
			samsung,pins = "gpc1-3\0gpc1-2";
		};

		i2c4-bus {
			linux,phandle = <0x1e>;
			phandle = <0x1e>;
			samsung,pin-drv = <0x00>;
			samsung,pin-function = <0x02>;
			samsung,pin-pud = <0x03>;
			samsung,pins = "gpc4-1\0gpc4-0";
		};

		i2c5-bus {
			linux,phandle = <0x2a>;
			phandle = <0x2a>;
			samsung,pin-drv = <0x00>;
			samsung,pin-function = <0x02>;
			samsung,pin-pud = <0x03>;
			samsung,pins = "gpc4-3\0gpc4-2";
		};

		initial-state {
			linux,phandle = <0x06>;
			phandle = <0x06>;

			gpd1-2 {
				samsung,pin-drv = <0x00>;
				samsung,pin-function = <0x00>;
				samsung,pin-pud = <0x00>;
				samsung,pins = "gpd1-2";
			};

			gpd1-3 {
				samsung,pin-drv = <0x00>;
				samsung,pin-function = <0x00>;
				samsung,pin-pud = <0x00>;
				samsung,pins = "gpd1-3";
			};

			gpd1-4 {
				samsung,pin-drv = <0x00>;
				samsung,pin-function = <0x00>;
				samsung,pin-pud = <0x00>;
				samsung,pins = "gpd1-4";
			};

			gpd1-5 {
				samsung,pin-drv = <0x00>;
				samsung,pin-function = <0x00>;
				samsung,pin-pud = <0x01>;
				samsung,pins = "gpd1-5";
			};

			gpe0-2 {
				samsung,pin-drv = <0x00>;
				samsung,pin-function = <0x00>;
				samsung,pin-pud = <0x01>;
				samsung,pins = "gpe0-2";
			};
		};

		nfc-pwr-en {
			linux,phandle = <0x29>;
			phandle = <0x29>;
			samsung,pin-function = <0x01>;
			samsung,pin-pud = <0x00>;
			samsung,pins = "gpf1-0";
		};

		nfc_firm {
			linux,phandle = <0x24>;
			phandle = <0x24>;
			samsung,pin-function = <0x01>;
			samsung,pin-pud = <0x01>;
			samsung,pin-val = <0x00>;
			samsung,pins = "gpd1-0";
		};

		nfc_pvdd_en {
			samsung,pin-function = <0x01>;
			samsung,pin-pud = <0x03>;
			samsung,pin-val = <0x00>;
			samsung,pins = "gpf1-0";
		};

		pwm-tout0 {
			samsung,pin-drv = <0x00>;
			samsung,pin-function = <0x02>;
			samsung,pin-pud = <0x01>;
			samsung,pins = "gpc0-1";
		};

		pwm-tout1 {
			samsung,pin-drv = <0x00>;
			samsung,pin-function = <0x02>;
			samsung,pin-pud = <0x01>;
			samsung,pins = "gpc0-2";
		};

		sleep-state {
			linux,phandle = <0x07>;
			phandle = <0x07>;

			gpc0-1 {
				samsung,pin-con-pdn = <0x03>;
				samsung,pin-pud-pdn = <0x00>;
				samsung,pins = "gpc0-1";
			};

			gpc0-2 {
				samsung,pin-con-pdn = <0x03>;
				samsung,pin-pud-pdn = <0x00>;
				samsung,pins = "gpc0-2";
			};

			gpc1-2 {
				samsung,pin-con-pdn = <0x03>;
				samsung,pin-pud-pdn = <0x03>;
				samsung,pins = "gpc1-2";
			};

			gpc1-3 {
				samsung,pin-con-pdn = <0x03>;
				samsung,pin-pud-pdn = <0x03>;
				samsung,pins = "gpc1-3";
			};

			gpc4-0 {
				samsung,pin-con-pdn = <0x02>;
				samsung,pin-pud-pdn = <0x03>;
				samsung,pins = "gpc4-0";
			};

			gpc4-1 {
				samsung,pin-con-pdn = <0x02>;
				samsung,pin-pud-pdn = <0x03>;
				samsung,pins = "gpc4-1";
			};

			gpc4-2 {
				samsung,pin-con-pdn = <0x02>;
				samsung,pin-pud-pdn = <0x03>;
				samsung,pins = "gpc4-2";
			};

			gpc4-3 {
				samsung,pin-con-pdn = <0x02>;
				samsung,pin-pud-pdn = <0x03>;
				samsung,pins = "gpc4-3";
			};

			gpd1-0 {
				samsung,pin-con-pdn = <0x03>;
				samsung,pin-pud-pdn = <0x01>;
				samsung,pins = "gpd1-0";
			};

			gpd1-1 {
				samsung,pin-con-pdn = <0x02>;
				samsung,pin-pud-pdn = <0x01>;
				samsung,pins = "gpd1-1";
			};

			gpd1-2 {
				samsung,pin-con-pdn = <0x02>;
				samsung,pin-pud-pdn = <0x00>;
				samsung,pins = "gpd1-2";
			};

			gpd1-3 {
				samsung,pin-con-pdn = <0x02>;
				samsung,pin-pud-pdn = <0x00>;
				samsung,pins = "gpd1-3";
			};

			gpd1-4 {
				samsung,pin-con-pdn = <0x02>;
				samsung,pin-pud-pdn = <0x00>;
				samsung,pins = "gpd1-4";
			};

			gpd1-5 {
				samsung,pin-con-pdn = <0x02>;
				samsung,pin-pud-pdn = <0x01>;
				samsung,pins = "gpd1-5";
			};

			gpd1-6 {
				samsung,pin-con-pdn = <0x02>;
				samsung,pin-pud-pdn = <0x01>;
				samsung,pins = "gpd1-6";
			};

			gpe0-0 {
				samsung,pin-con-pdn = <0x02>;
				samsung,pin-pud-pdn = <0x01>;
				samsung,pins = "gpe0-0";
			};

			gpe0-1 {
				samsung,pin-con-pdn = <0x02>;
				samsung,pin-pud-pdn = <0x01>;
				samsung,pins = "gpe0-1";
			};

			gpe0-2 {
				samsung,pin-con-pdn = <0x02>;
				samsung,pin-pud-pdn = <0x01>;
				samsung,pins = "gpe0-2";
			};

			gpf0-0 {
				samsung,pin-con-pdn = <0x02>;
				samsung,pin-pud-pdn = <0x01>;
				samsung,pins = "gpf0-0";
			};

			gpf0-1 {
				samsung,pin-con-pdn = <0x02>;
				samsung,pin-pud-pdn = <0x01>;
				samsung,pins = "gpf0-1";
			};

			gpf0-2 {
				samsung,pin-con-pdn = <0x02>;
				samsung,pin-pud-pdn = <0x01>;
				samsung,pins = "gpf0-2";
			};

			gpf0-3 {
				samsung,pin-con-pdn = <0x02>;
				samsung,pin-pud-pdn = <0x01>;
				samsung,pins = "gpf0-3";
			};

			gpf1-0 {
				samsung,pin-con-pdn = <0x03>;
				samsung,pin-pud-pdn = <0x00>;
				samsung,pins = "gpf1-0";
			};

			gpf1-1 {
				samsung,pin-con-pdn = <0x02>;
				samsung,pin-pud-pdn = <0x01>;
				samsung,pins = "gpf1-1";
			};

			gpf3-0 {
				samsung,pin-con-pdn = <0x02>;
				samsung,pin-pud-pdn = <0x03>;
				samsung,pins = "gpf3-0";
			};

			gpf3-1 {
				samsung,pin-con-pdn = <0x02>;
				samsung,pin-pud-pdn = <0x03>;
				samsung,pins = "gpf3-1";
			};

			gpf3-2 {
				samsung,pin-con-pdn = <0x02>;
				samsung,pin-pud-pdn = <0x03>;
				samsung,pins = "gpf3-2";
			};

			gpf3-3 {
				samsung,pin-con-pdn = <0x02>;
				samsung,pin-pud-pdn = <0x03>;
				samsung,pins = "gpf3-3";
			};
		};

		spi1-bus {
			linux,phandle = <0x48>;
			phandle = <0x48>;
			samsung,pin-drv = <0x00>;
			samsung,pin-function = <0x02>;
			samsung,pin-pud = <0x03>;
			samsung,pins = "gpf3-3\0gpf3-2\0gpf3-0";
		};

		spi1-cs-0 {
			samsung,pin-drv = <0x00>;
			samsung,pin-function = <0x01>;
			samsung,pin-pud = <0x03>;
			samsung,pins = "gpf3-1";
		};

		spi1-cs-1 {
			samsung,pin-drv = <0x00>;
			samsung,pin-function = <0x01>;
			samsung,pin-pud = <0x03>;
			samsung,pins = "gpd1-0";
		};

		spk-amp-i2c {
			linux,phandle = <0x30>;
			phandle = <0x30>;
			samsung,pin-drv = <0x00>;
			samsung,pin-function = <0x03>;
			samsung,pin-pud = <0x03>;
			samsung,pins = "gpf3-0\0gpf3-1";
		};

		uart1-bus {
			linux,phandle = <0x11>;
			phandle = <0x11>;
			samsung,pin-function = <0x04>;
			samsung,pin-pud = <0x00>;
			samsung,pins = "gpc4-3\0gpc4-2";
		};
	};

	pinctrl@139C0000 {
		compatible = "samsung,exynos7570-pinctrl";
		interrupts = <0x00 0x1b7 0x00>;
		pinctrl-0 = <0x05>;
		pinctrl-names = "sleep";
		reg = <0x00 0x139c0000 0x1000>;

		gpc2 {
			#gpio-cells = <0x02>;
			#interrupt-cells = <0x02>;
			gpio-controller;
			interrupt-controller;
			linux,phandle = <0x21>;
			phandle = <0x21>;
		};

		gpio-nfc {
			samsung,pin-con-pdn = <0x03>;
			samsung,pin-drv = <0x00>;
			samsung,pin-function = <0x01>;
			samsung,pin-pud = <0x00>;
			samsung,pin-val = <0x01>;
			samsung,pins = "gpc2-2";
		};

		i2c2-bus {
			linux,phandle = <0x19>;
			phandle = <0x19>;
			samsung,pin-drv = <0x00>;
			samsung,pin-function = <0x02>;
			samsung,pin-pud = <0x00>;
			samsung,pins = "gpc2-1\0gpc2-0";
		};

		nfc_clk_req {
			linux,phandle = <0x27>;
			phandle = <0x27>;
			samsung,pin-drv = <0x00>;
			samsung,pin-function = <0x02>;
			samsung,pin-pud = <0x01>;
			samsung,pins = "gpc2-3";
		};

		nfc_pd {
			linux,phandle = <0x23>;
			phandle = <0x23>;
			samsung,pin-drv = <0x00>;
			samsung,pin-function = <0x02>;
			samsung,pin-pud = <0x03>;
			samsung,pins = "gpc2-2";
		};

		sleep-state {
			linux,phandle = <0x05>;
			phandle = <0x05>;

			gpc2-0 {
				samsung,pin-con-pdn = <0x02>;
				samsung,pin-pud-pdn = <0x00>;
				samsung,pins = "gpc2-0";
			};

			gpc2-1 {
				samsung,pin-con-pdn = <0x02>;
				samsung,pin-pud-pdn = <0x00>;
				samsung,pins = "gpc2-1";
			};

			gpc2-2 {
				samsung,pin-con-pdn = <0x03>;
				samsung,pin-pud-pdn = <0x00>;
				samsung,pins = "gpc2-2";
			};

			gpc2-3 {
				samsung,pin-con-pdn = <0x03>;
				samsung,pin-pud-pdn = <0x00>;
				samsung,pins = "gpc2-3";
			};
		};
	};

	pinctrl@139D0000 {
		compatible = "samsung,exynos7570-pinctrl";
		interrupts = <0x00 0x1b8 0x00>;
		pinctrl-0 = <0x08>;
		pinctrl-names = "sleep";
		reg = <0x00 0x139d0000 0x1000>;

		attn-i2c {
			linux,phandle = <0x1a>;
			phandle = <0x1a>;
			samsung,pin-drv = <0x00>;
			samsung,pin-function = <0x02>;
			samsung,pin-pud = <0x03>;
			samsung,pins = "gpc3-1\0gpc3-0";
		};

		attn-input {
			linux,phandle = <0x1c>;
			phandle = <0x1c>;
			samsung,pin-drv = <0x00>;
			samsung,pin-function = <0x00>;
			samsung,pin-pud = <0x00>;
			samsung,pins = "gpc3-2";
		};

		attn-irq {
			linux,phandle = <0x1b>;
			phandle = <0x1b>;
			samsung,pin-drv = <0x00>;
			samsung,pin-function = <0x0f>;
			samsung,pin-pud = <0x00>;
			samsung,pins = "gpc3-2";
		};

		gpc3 {
			#gpio-cells = <0x02>;
			#interrupt-cells = <0x02>;
			gpio-controller;
			interrupt-controller;
			linux,phandle = <0x1d>;
			phandle = <0x1d>;
		};

		gpd2 {
			#gpio-cells = <0x02>;
			#interrupt-cells = <0x02>;
			gpio-controller;
			interrupt-controller;
			linux,phandle = <0x73>;
			phandle = <0x73>;
		};

		i2c3-bus {
			samsung,pin-drv = <0x00>;
			samsung,pin-function = <0x02>;
			samsung,pin-pud = <0x03>;
			samsung,pins = "gpc3-1\0gpc3-0";
		};

		sleep-state {
			linux,phandle = <0x08>;
			phandle = <0x08>;

			gpc3-0 {
				samsung,pin-con-pdn = <0x02>;
				samsung,pin-pud-pdn = <0x03>;
				samsung,pins = "gpc3-0";
			};

			gpc3-1 {
				samsung,pin-con-pdn = <0x02>;
				samsung,pin-pud-pdn = <0x03>;
				samsung,pins = "gpc3-1";
			};

			gpc3-2 {
				samsung,pin-con-pdn = <0x02>;
				samsung,pin-pud-pdn = <0x00>;
				samsung,pins = "gpc3-2";
			};
		};
	};

	pinctrl@139E0000 {
		compatible = "samsung,exynos7570-pinctrl";
		interrupts = <0x00 0x1b9 0x00>;
		pinctrl-0 = <0x02>;
		pinctrl-names = "sleep";
		reg = <0x00 0x139e0000 0x1000>;

		fm-lna-en {
			linux,phandle = <0x71>;
			phandle = <0x71>;
			samsung,pin-function = <0x01>;
			samsung,pin-pud = <0x00>;
			samsung,pin-val = <0x00>;
			samsung,pins = "gpc7-4";
		};

		gpc7 {
			#gpio-cells = <0x02>;
			#interrupt-cells = <0x02>;
			gpio-controller;
			interrupt-controller;
			linux,phandle = <0x70>;
			phandle = <0x70>;
		};

		sleep-state {
			linux,phandle = <0x02>;
			phandle = <0x02>;

			gpc7-0 {
				samsung,pin-con-pdn = <0x02>;
				samsung,pin-pud-pdn = <0x01>;
				samsung,pins = "gpc7-0";
			};

			gpc7-1 {
				samsung,pin-con-pdn = <0x02>;
				samsung,pin-pud-pdn = <0x01>;
				samsung,pins = "gpc7-1";
			};

			gpc7-2 {
				samsung,pin-con-pdn = <0x02>;
				samsung,pin-pud-pdn = <0x01>;
				samsung,pins = "gpc7-2";
			};

			gpc7-3 {
				samsung,pin-con-pdn = <0x02>;
				samsung,pin-pud-pdn = <0x01>;
				samsung,pins = "gpc7-3";
			};

			gpc7-4 {
				samsung,pin-con-pdn = <0x03>;
				samsung,pin-pud-pdn = <0x00>;
				samsung,pins = "gpc7-4";
			};
		};

		spi0-bus {
			linux,phandle = <0x47>;
			phandle = <0x47>;
			samsung,pin-drv = <0x00>;
			samsung,pin-function = <0x02>;
			samsung,pin-pud = <0x03>;
			samsung,pins = "gpc7-3\0gpc7-2\0gpc7-0";
		};

		spi0-cs-0 {
			samsung,pin-drv = <0x00>;
			samsung,pin-function = <0x01>;
			samsung,pin-pud = <0x03>;
			samsung,pins = "gpc7-1";
		};

		spi0-cs-1 {
			samsung,pin-drv = <0x00>;
			samsung,pin-function = <0x01>;
			samsung,pin-pud = <0x03>;
			samsung,pins = "gpc7-4";
		};
	};

	pinctrl@139F0000 {
		compatible = "samsung,exynos7570-pinctrl";
		interrupts = <0x00 0x00 0x00 0x00 0x01 0x00 0x00 0x02 0x00 0x00 0x03 0x00 0x00 0x04 0x00 0x00 0x05 0x00 0x00 0x06 0x00 0x00 0x07 0x00 0x00 0x08 0x00 0x00 0x09 0x00 0x00 0x0a 0x00 0x00 0x0b 0x00 0x00 0x0c 0x00 0x00 0x0d 0x00 0x00 0x0e 0x00 0x00 0x0f 0x00>;
		reg = <0x00 0x139f0000 0x1000>;

		acc_int {
			linux,phandle = <0x2b>;
			phandle = <0x2b>;
			samsung,pin-drv = <0x00>;
			samsung,pin-function = <0x00>;
			samsung,pin-pud = <0x00>;
			samsung,pins = "gpa2-2";
		};

		cp_gpio {
			samsung,pin-function = <0x04>;
			samsung,pin-pud = <0x00>;
			samsung,pins = "gpa1-7\0gpa2-1";
		};

		cp_gpio_iot {
			samsung,pin-function = <0x04>;
			samsung,pin-pud = <0x00>;
			samsung,pins = "gpa1-3\0gpa2-0\0gpa2-2\0gpa2-7";
		};

		cp_gpio_j2corelte {
			samsung,pin-function = <0x04>;
			samsung,pin-pud = <0x00>;
			samsung,pins = "gpa1-7\0gpa2-6\0gpa2-7";
		};

		cp_gpio_j3neoelte {
			samsung,pin-function = <0x04>;
			samsung,pin-pud = <0x00>;
			samsung,pins = "gpa1-7\0gpa2-2\0gpa2-3\0gpa2-4\0gpa2-5\0gpa2-6\0gpa2-7";
		};

		cp_gpio_j3pop {
			samsung,pin-function = <0x04>;
			samsung,pin-pud = <0x00>;
			samsung,pins = "gpa2-3";
		};

		cp_gpio_j3pop_old {
			samsung,pin-function = <0x04>;
			samsung,pin-pud = <0x00>;
			samsung,pins = "gpa1-3";
		};

		cp_gpio_j3y17_rev0 {
			samsung,pin-function = <0x04>;
			samsung,pin-pud = <0x00>;
			samsung,pins = "gpa1-7\0gpa2-6\0gpa2-5";
		};

		cp_gpio_j3y17_rev1 {
			samsung,pin-function = <0x04>;
			samsung,pin-pud = <0x00>;
			samsung,pins = "gpa1-7\0gpa2-6";
		};

		cp_gpio_j4lte {
			samsung,pin-function = <0x04>;
			samsung,pin-pud = <0x00>;
			samsung,pins = "gpa2-6";
		};

		cp_gpio_on5 {
			samsung,pin-function = <0x04>;
			samsung,pin-pud = <0x00>;
			samsung,pins = "gpa1-7";
		};

		cp_gpio_tabes_vzw {
			samsung,pin-function = <0x04>;
			samsung,pin-pud = <0x00>;
			samsung,pins = "gpa2-0\0gpa2-1\0gpa2-2";
		};

		cp_gpio_tabes_vzw_rev1 {
			samsung,pin-function = <0x04>;
			samsung,pin-pud = <0x00>;
			samsung,pins = "gpa1-7\0gpa2-0\0gpa2-1\0gpa2-2";
		};

		cp_gpio_w {
			samsung,pin-function = <0x04>;
			samsung,pin-pud = <0x00>;
			samsung,pins = "gpa2-5\0gpa2-6";
		};

		cp_gpio_x4 {
			linux,phandle = <0x7e>;
			phandle = <0x7e>;
			samsung,pin-function = <0x04>;
			samsung,pin-pud = <0x00>;
			samsung,pins = "gpa1-7\0gpa2-0\0gpa2-1\0gpa2-4";
		};

		dwmmc2_cd_ext_irq {
			linux,phandle = <0x59>;
			phandle = <0x59>;
			samsung,pin-drv = <0x04>;
			samsung,pin-function = <0x0f>;
			samsung,pin-pud = <0x00>;
			samsung,pins = "gpa0-1";
		};

		etc0 {
			#gpio-cells = <0x02>;
			#interrupt-cells = <0x02>;
			gpio-controller;
			interrupt-controller;
		};

		etc1 {
			#gpio-cells = <0x02>;
			#interrupt-cells = <0x02>;
			gpio-controller;
			interrupt-controller;
		};

		fimc-is-flash {
			linux,phandle = <0x7c>;
			phandle = <0x7c>;
			samsung,pin-drv = <0x00>;
			samsung,pin-function = <0x01>;
			samsung,pin-pud = <0x00>;
			samsung,pins = "gpa0-0";
		};

		fimc_is_mclk1_fn {
			samsung,pin-drv = <0x01>;
			samsung,pin-function = <0x02>;
			samsung,pin-pud = <0x00>;
			samsung,pins = "gpa2-3";
		};

		fimc_is_mclk1_in {
			samsung,pin-drv = <0x00>;
			samsung,pin-function = <0x00>;
			samsung,pin-pud = <0x00>;
			samsung,pins = "gpa2-3";
		};

		fimc_is_mclk1_out {
			samsung,pin-drv = <0x02>;
			samsung,pin-function = <0x01>;
			samsung,pin-pud = <0x01>;
			samsung,pins = "gpa2-3";
		};

		gpa0 {
			#gpio-cells = <0x02>;
			#interrupt-cells = <0x02>;
			gpio-controller;
			interrupt-controller;
			interrupt-parent = <0x01>;
			interrupts = <0x00 0x00 0x00 0x00 0x01 0x00 0x00 0x02 0x00 0x00 0x03 0x00 0x00 0x04 0x00 0x00 0x05 0x00 0x00 0x06 0x00 0x00 0x07 0x00>;
			linux,phandle = <0x22>;
			phandle = <0x22>;
		};

		gpa1 {
			#gpio-cells = <0x02>;
			#interrupt-cells = <0x03>;
			gpio-controller;
			interrupt-controller;
			interrupt-parent = <0x01>;
			interrupts = <0x00 0x08 0x00 0x00 0x09 0x00 0x00 0x0a 0x00 0x00 0x0b 0x00 0x00 0x0c 0x00 0x00 0x0d 0x00 0x00 0x0e 0x00 0x00 0x0f 0x00>;
			linux,phandle = <0x18>;
			phandle = <0x18>;
		};

		gpa2 {
			#gpio-cells = <0x02>;
			#interrupt-cells = <0x02>;
			gpio-controller;
			interrupt-controller;
			linux,phandle = <0x2c>;
			phandle = <0x2c>;
		};

		gpq0 {
			#gpio-cells = <0x02>;
			#interrupt-cells = <0x02>;
			gpio-controller;
			interrupt-controller;
		};

		grip_irq {
			linux,phandle = <0x33>;
			phandle = <0x33>;
			samsung,pin-drv = <0x00>;
			samsung,pin-function = <0x00>;
			samsung,pin-pud = <0x00>;
			samsung,pins = "gpa1-4";
		};

		hs-i2c5-bus {
			linux,phandle = <0x3d>;
			phandle = <0x3d>;
			samsung,pin-drv = <0x00>;
			samsung,pin-function = <0x02>;
			samsung,pin-pud = <0x03>;
			samsung,pins = "gpa2-0\0gpa1-7";
		};

		hs-i2c6-bus {
			linux,phandle = <0x3e>;
			phandle = <0x3e>;
			samsung,pin-drv = <0x00>;
			samsung,pin-function = <0x02>;
			samsung,pin-pud = <0x03>;
			samsung,pins = "gpa2-2\0gpa2-1";
		};

		hs-i2c7-bus {
			linux,phandle = <0x3f>;
			phandle = <0x3f>;
			samsung,pin-drv = <0x00>;
			samsung,pin-function = <0x02>;
			samsung,pin-pud = <0x03>;
			samsung,pins = "gpa2-5\0gpa2-4";
		};

		hs-i2c8-bus {
			linux,phandle = <0x40>;
			phandle = <0x40>;
			samsung,pin-drv = <0x00>;
			samsung,pin-function = <0x02>;
			samsung,pin-pud = <0x03>;
			samsung,pins = "gpa2-7\0gpa2-6";
		};

		i2c6-bus {
			linux,phandle = <0x2f>;
			phandle = <0x2f>;
			samsung,pin-drv = <0x00>;
			samsung,pin-function = <0x02>;
			samsung,pin-pud = <0x03>;
			samsung,pins = "gpa1-6\0gpa1-5";
		};

		if-irq {
			linux,phandle = <0x45>;
			phandle = <0x45>;
			samsung,pin-drv = <0x03>;
			samsung,pin-pud = <0x03>;
			samsung,pins = "gpa0-5";
		};

		key-back {
			linux,phandle = <0x79>;
			phandle = <0x79>;
			samsung,pin-drv = <0x00>;
			samsung,pin-function = <0x0f>;
			samsung,pin-pud = <0x03>;
			samsung,pins = "gpa2-6";
		};

		key-home {
			linux,phandle = <0x77>;
			phandle = <0x77>;
			samsung,pin-drv = <0x00>;
			samsung,pin-function = <0x0f>;
			samsung,pin-pud = <0x03>;
			samsung,pins = "gpa0-4";
		};

		key-multi {
			linux,phandle = <0x7a>;
			phandle = <0x7a>;
			samsung,pin-drv = <0x00>;
			samsung,pin-function = <0x0f>;
			samsung,pin-pud = <0x03>;
			samsung,pins = "gpa2-7";
		};

		key-recent {
			linux,phandle = <0x78>;
			phandle = <0x78>;
			samsung,pin-drv = <0x00>;
			samsung,pin-function = <0x0f>;
			samsung,pin-pud = <0x03>;
			samsung,pins = "gpa2-5";
		};

		key-voldown {
			linux,phandle = <0x75>;
			phandle = <0x75>;
			samsung,pin-drv = <0x00>;
			samsung,pin-function = <0x0f>;
			samsung,pin-pud = <0x03>;
			samsung,pins = "gpa2-3";
		};

		key-volup {
			linux,phandle = <0x76>;
			phandle = <0x76>;
			samsung,pin-drv = <0x00>;
			samsung,pin-function = <0x0f>;
			samsung,pin-pud = <0x03>;
			samsung,pins = "gpa0-7";
		};

		muic-irq {
			linux,phandle = <0x17>;
			phandle = <0x17>;
			samsung,pin-drv = <0x00>;
			samsung,pin-pud = <0x00>;
			samsung,pins = "gpa1-1";
		};

		nfc-clk {
			linux,phandle = <0x26>;
			phandle = <0x26>;
			samsung,pin-function = <0x02>;
			samsung,pin-pud = <0x00>;
			samsung,pins = "gpq0-0";
		};

		nfc-clkreq-int {
			linux,phandle = <0x28>;
			phandle = <0x28>;
			samsung,pin-function = <0x00>;
			samsung,pin-pud = <0x00>;
			samsung,pins = "gpa0-6";
		};

		nfc-int {
			linux,phandle = <0x25>;
			phandle = <0x25>;
			samsung,pin-function = <0x00>;
			samsung,pin-pud = <0x00>;
			samsung,pins = "gpa1-3";
		};

		prox_int {
			linux,phandle = <0x2e>;
			phandle = <0x2e>;
			samsung,pin-drv = <0x00>;
			samsung,pin-function = <0x00>;
			samsung,pin-pud = <0x00>;
			samsung,pins = "gpa1-0";
		};

		sim0_gpio_on5 {
			samsung,pin-function = <0x0f>;
			samsung,pin-pud = <0x00>;
			samsung,pins = "gpa2-4";
		};

		sim1_gpio_on5 {
			samsung,pin-function = <0x0f>;
			samsung,pin-pud = <0x00>;
			samsung,pins = "gpa1-4";
		};

		sim_gpio_default_on5 {
			samsung,pin-function = <0x00>;
			samsung,pin-pud = <0x00>;
			samsung,pins = "gpa2-4";
		};

		spi2-bus {
			linux,phandle = <0x49>;
			phandle = <0x49>;
			samsung,pin-drv = <0x00>;
			samsung,pin-function = <0x02>;
			samsung,pin-pud = <0x03>;
			samsung,pins = "gpa2-0\0gpa1-7\0gpa2-2";
		};

		spi2-cs-0 {
			samsung,pin-drv = <0x00>;
			samsung,pin-function = <0x01>;
			samsung,pin-pud = <0x03>;
			samsung,pins = "gpa2-1";
		};

		spi3-bus {
			linux,phandle = <0x4a>;
			phandle = <0x4a>;
			samsung,pin-drv = <0x00>;
			samsung,pin-function = <0x02>;
			samsung,pin-pud = <0x03>;
			samsung,pins = "gpa2-5\0gpa2-4\0gpa2-7";
		};

		spi3-cs-0 {
			samsung,pin-drv = <0x00>;
			samsung,pin-function = <0x01>;
			samsung,pin-pud = <0x03>;
			samsung,pins = "gpa2-6";
		};

		uart2-bus {
			linux,phandle = <0x12>;
			phandle = <0x12>;
			samsung,pin-function = <0x03>;
			samsung,pin-pud = <0x00>;
			samsung,pins = "gpa1-6\0gpa1-5";
		};

		uart2-sleep {
			linux,phandle = <0x13>;
			phandle = <0x13>;
			samsung,pin-function = <0x00>;
			samsung,pin-pud = <0x01>;
			samsung,pins = "gpa1-6";
		};

		uart3-bus-dual {
			samsung,pin-function = <0x02>;
			samsung,pin-pud = <0x00>;
			samsung,pins = "gpa2-0\0gpa1-7";
		};

		uart3-bus-single {
			linux,phandle = <0x14>;
			phandle = <0x14>;
			samsung,pin-function = <0x02>;
			samsung,pin-pud = <0x00>;
			samsung,pins = "gpa2-0\0gpa1-7\0gpa2-1\0gpa2-2";
		};

		uart4-bus-dual {
			samsung,pin-function = <0x02>;
			samsung,pin-pud = <0x00>;
			samsung,pins = "gpa2-5\0gpa2-4";
		};

		uart4-bus-single {
			linux,phandle = <0x15>;
			phandle = <0x15>;
			samsung,pin-function = <0x02>;
			samsung,pin-pud = <0x00>;
			samsung,pins = "gpa2-5\0gpa2-4\0gpa2-6\0gpa2-7";
		};

		wakeup-interrupt-controller {
			compatible = "samsung,exynos4210-wakeup-eint";
			interrupt-parent = <0x01>;
			interrupts = <0x00 0x10 0x00>;
			samsung,eint-flt-conf;
		};
	};

	pinctrl@148C0000 {
		compatible = "samsung,exynos7570-pinctrl";
		interrupts = <0x00 0x44 0x00>;
		pinctrl-0 = <0x03>;
		pinctrl-names = "sleep";
		reg = <0x00 0x148c0000 0x1000>;

		fm-speedy-bus {
			samsung,pin-drv = <0x02>;
			samsung,pin-function = <0x02>;
			samsung,pin-pud = <0x03>;
			samsung,pins = "gpz1-6";
		};

		fm-speedy-bus-idle {
			samsung,pin-drv = <0x02>;
			samsung,pin-function = <0x00>;
			samsung,pin-pud = <0x03>;
			samsung,pins = "gpz1-6";
		};

		gpz1 {
			#gpio-cells = <0x02>;
			#interrupt-cells = <0x02>;
			gpio-controller;
			interrupt-controller;
		};

		i2s-amp-bus {
			samsung,pin-drv = <0x02>;
			samsung,pin-function = <0x02>;
			samsung,pin-pud = <0x03>;
			samsung,pins = "gpz1-5";
		};

		i2s-amp-bus-idle {
			samsung,pin-drv = <0x02>;
			samsung,pin-function = <0x00>;
			samsung,pin-pud = <0x03>;
			samsung,pins = "gpz1-5";
		};

		i2s-codec-clk {
			linux,phandle = <0x3a>;
			phandle = <0x3a>;
			samsung,pin-drv = <0x00>;
			samsung,pin-function = <0x02>;
			samsung,pin-pud = <0x01>;
			samsung,pins = "gpz1-4";
		};

		i2s-pmic-amp-bus {
			linux,phandle = <0x39>;
			phandle = <0x39>;
			samsung,pin-drv = <0x00>;
			samsung,pin-function = <0x02>;
			samsung,pin-pud = <0x01>;
			samsung,pins = "gpz1-0\0gpz1-1\0gpz1-2\0gpz1-3\0gpz1-4\0gpz1-5";
		};

		i2s-pmic-amp-bus-idle {
			linux,phandle = <0x3b>;
			phandle = <0x3b>;
			samsung,pin-drv = <0x00>;
			samsung,pin-function = <0x00>;
			samsung,pin-pud = <0x01>;
			samsung,pins = "gpz1-0\0gpz1-1\0gpz1-2\0gpz1-3\0gpz1-4\0gpz1-5";
		};

		i2s-pmic-bus {
			samsung,pin-drv = <0x00>;
			samsung,pin-function = <0x02>;
			samsung,pin-pud = <0x01>;
			samsung,pins = "gpz1-0\0gpz1-1\0gpz1-2\0gpz1-3";
		};

		i2s-pmic-bus-idle {
			samsung,pin-drv = <0x00>;
			samsung,pin-function = <0x00>;
			samsung,pin-pud = <0x01>;
			samsung,pins = "gpz1-0\0gpz1-1\0gpz1-2\0gpz1-3";
		};

		sleep-state {
			linux,phandle = <0x03>;
			phandle = <0x03>;

			gpz1-0 {
				samsung,pin-con-pdn = <0x02>;
				samsung,pin-pud-pdn = <0x01>;
				samsung,pins = "gpz1-0";
			};

			gpz1-1 {
				samsung,pin-con-pdn = <0x02>;
				samsung,pin-pud-pdn = <0x01>;
				samsung,pins = "gpz1-1";
			};

			gpz1-2 {
				samsung,pin-con-pdn = <0x02>;
				samsung,pin-pud-pdn = <0x01>;
				samsung,pins = "gpz1-2";
			};

			gpz1-3 {
				samsung,pin-con-pdn = <0x02>;
				samsung,pin-pud-pdn = <0x01>;
				samsung,pins = "gpz1-3";
			};

			gpz1-4 {
				samsung,pin-con-pdn = <0x02>;
				samsung,pin-pud-pdn = <0x01>;
				samsung,pins = "gpz1-4";
			};

			gpz1-5 {
				samsung,pin-con-pdn = <0x02>;
				samsung,pin-pud-pdn = <0x01>;
				samsung,pins = "gpz1-5";
			};

			gpz1-6 {
				samsung,pin-con-pdn = <0x02>;
				samsung,pin-pud-pdn = <0x01>;
				samsung,pins = "gpz1-6";
			};
		};
	};

	psci {
		compatible = "arm,psci";
		cpu_off = <0x84000002>;
		cpu_on = <0xc4000003>;
		cpu_suspend = <0xc4000001>;
		method = "smc";
	};

	pwm-clock-controller@13970000 {
		#clock-cells = <0x01>;
		compatible = "samsung,exynos-pwm-clock";
		linux,phandle = <0x6d>;
		phandle = <0x6d>;
		reg = <0x00 0x13970000 0x50>;
	};

	pwm@13970000 {
		#pwm-cells = <0x03>;
		clock-names = "gate_timers\0sclk_pwm\0pwm-scaler0\0pwm-scaler1\0pwm-tdiv0\0pwm-tdiv1\0pwm-tdiv2\0pwm-tdiv3\0pwm-tin0\0pwm-tin1\0pwm-tin2\0pwm-tin3";
		clocks = <0x10 0x14a 0x10 0x14b 0x6d 0x01 0x6d 0x02 0x6d 0x05 0x6d 0x06 0x6d 0x07 0x6d 0x08 0x6d 0x0a 0x6d 0x0b 0x6d 0x0c 0x6d 0x0d>;
		compatible = "samsung,s3c6400-pwm";
		reg = <0x00 0x13970000 0x1000>;
		samsung,pwm-outputs = <0x00 0x01 0x02 0x03 0x04>;
		samsung,pwm-sclk-ctrl;
		status = "ok";
	};

	reboot {
		compatible = "exynos,reboot";
		pmu_base = <0x11c80000>;
	};

	reserved-memory {
		#address-cells = <0x02>;
		#size-cells = <0x01>;
		ranges;

		camera {
			compatible = "exynos8890-ion,camera";
			id = <0x0a>;
			reg = <0x00 0x710ef000 0x1000>;
		};

		crypto {
			compatible = "exynos8890-ion,crypto";
			id = <0x01>;
			reg = <0x00 0x79400000 0x800000>;
			reusable;
		};

		gnss_if {
			compatible = "exynos,gnss_if";
			reg = <0x00 0x7e100000 0x200000>;
		};

		modem_if {
			compatible = "exynos,modem_if";
			reg = <0x00 0x73400000 0x5c00000>;
		};

		tima_region@0x52800000 {
			compatible = "removed-dma-pool";
			reg = <0x00 0x52800000 0x200000>;
		};

		video_frame {
			compat-id = <0x1a 0x1d>;
			compatible = "exynos8890-ion,vframe";
			id = <0x05>;
			ion,bulk_reclaim;
			reg = <0x00 0x79c00000 0x3800000>;
			reusable;
			secure;
		};

		video_nfw {
			compatible = "exynos7570-mfc,vnfw";
			fixed_lower_base = <0x40000000>;
			fixed_upper_base = <0xffffff80>;
			reg = <0x00 0x710f0000 0x110000>;
		};

		video_scaler {
			compat-id = <0x1c>;
			compatible = "exynos8890-ion,vscaler";
			id = <0x06>;
			reg = <0x00 0x71200000 0x1000000>;
			reusable;
			secure;
		};

		video_stream {
			compat-id = <0x19 0x1f>;
			compatible = "exynos8890-ion,vstream";
			id = <0x03>;
			reg = <0x00 0x72200000 0x1200000>;
			secure;
		};

		wifibt_if {
			compatible = "exynos,wifibt_if";
			reg = <0x00 0x79000000 0x400000>;
		};
	};

	rtc@101A0000 {
		clock-names = "gate_rtc";
		clocks = <0x10 0x176>;
		compatible = "samsung,s3c6410-rtc";
		interrupts = <0x00 0x5c 0x00 0x00 0x5d 0x00>;
		reg = <0x00 0x101a0000 0x100>;
	};

	s1403x@14880000 {
		clock-names = "audmixer_dout\0audmixer_aclk";
		clocks = <0x10 0x2e6 0x10 0x2c6>;
		compatible = "samsung,s1403x";
		linux,phandle = <0x88>;
		phandle = <0x88>;
		pinctrl-0 = <0x39 0x3a>;
		pinctrl-1 = <0x3b>;
		pinctrl-names = "default\0idle";
		reg = <0x00 0x14880000 0x200>;
		samsung,lpass-subip;
		status = "okay";
	};

	s2mpu06-charger {
		battery,chg_gpio_en = <0x00>;
		battery,chg_gpio_status = <0x00>;
		battery,chg_polarity_en = <0x00>;
		battery,chg_polarity_status = <0x00>;
		battery,is_1MHz_switching = <0x01>;
		compatible = "samsung,s2mpu06-charger";
		status = "disable";
	};

	s2mpu06-fuelgauge {
		compatible = "samsung,s2mpu06-fuelgauge";
		fuelgauge,capacity_calculation_type = <0x1c>;
		fuelgauge,capacity_full = <0xaf0>;
		fuelgauge,capacity_max = <0x3e8>;
		fuelgauge,capacity_max_margin = <0x46>;
		fuelgauge,capacity_min = <0x00>;
		fuelgauge,cell_character = <0xb8 0x0a 0xb8 0x0a 0x74 0x0a 0x26 0x0a 0x9a 0x09 0x27 0x09 0xbb 0x08 0x56 0x08 0xfb 0x07 0xad 0x07 0x32 0x07 0xe0 0x06 0xab 0x06 0x81 0x06 0x5e 0x06 0x43 0x06 0x27 0x06 0xfc 0x05 0xb4 0x05 0x7e 0x05 0x4b 0x05 0x87 0x02 0x2e 0x08 0x2e 0x08 0x00 0x08 0xbe 0x07 0x4e 0x07 0xde 0x06 0x6e 0x06 0xfe 0x05 0x8e 0x05 0x1e 0x05 0xae 0x04 0x3f 0x04 0xcf 0x03 0x5f 0x03 0xef 0x02 0x7f 0x02 0x0f 0x02 0x9f 0x01 0x2f 0x01 0xbf 0x00 0x50 0x00 0xec 0x0f 0xfe 0x29 0xdc 0x29 0x8a 0x29 0x4d 0x29 0x28 0x1f 0x23 0x10 0x21 0x21 0x14 0x21 0xf3 0xf7 0xe6 0xf7 0xda 0xde 0xca 0xd4 0xd3 0xd4 0x40 0x80 0x26 0x33 0x26 0x40 0x26 0x5c 0x26 0x5c 0x26 0x5c 0xff 0xff 0x02 0x05 0x14 0x0b 0x03 0x12 0x06 0x1c 0x0c 0x1c 0x10 0x1c 0x1f 0x1f 0x38 0x38 0x38 0x40 0x40 0x3f 0x40 0x3f 0x3f 0x3f 0x40 0x41 0x3d 0x39 0x3a 0x3b 0x3c 0x3e 0x42 0x55 0x7b 0xa4 0x0f 0xf0 0x0a 0x00 0x00 0x7b 0x0a 0x7b 0x0a 0x2e 0x0a 0xad 0x09 0x3b 0x09 0xce 0x08 0x78 0x08 0xf7 0x07 0xb5 0x07 0x6f 0x07 0xff 0x06 0xb7 0x06 0x89 0x06 0x66 0x06 0x4b 0x06 0x37 0x06 0x26 0x06 0x01 0x06 0xb3 0x05 0x89 0x05 0x6b 0x05 0xd5 0x02 0x6d 0x08 0x6d 0x08 0x00 0x08 0x93 0x07 0x26 0x07 0xb9 0x06 0x4c 0x06 0xde 0x05 0x71 0x05 0x04 0x05 0x97 0x04 0x2a 0x04 0xbd 0x03 0x50 0x03 0xe3 0x02 0x76 0x02 0x09 0x02 0x9c 0x01 0x2e 0x01 0xc1 0x00 0x54 0x00 0xf8 0x0f 0xfe 0x29 0xdc 0x29 0x8a 0x29 0x4d 0x29 0x28 0x1f 0x23 0x10 0x21 0x21 0x14 0x21 0xf3 0xf7 0xe6 0xf7 0xda 0xde 0xca 0xd4 0xd3 0xd4 0x40 0x80 0x26 0x33 0x26 0x40 0x26 0x5c 0x26 0x5c 0x26 0x5c 0xff 0xff 0x02 0x05 0x14 0x0b 0x03 0x12 0x06 0x1c 0x0c 0x1c 0x10 0x1c 0x1f 0x1f 0x38 0x38 0x38 0x40 0x40 0x3f 0x40 0x3f 0x3f 0x3f 0x40 0x41 0x3d 0x39 0x3a 0x3b 0x3c 0x3e 0x42 0x55 0x7b 0xa4 0x0f 0xf0 0x0a 0x00 0x00 0x4a 0x0a 0xfd 0x09 0x87 0x09 0x1f 0x09 0xbb 0x08 0x6c 0x08 0xf5 0x07 0xb9 0x07 0x73 0x07 0x0f 0x07 0xc6 0x06 0x98 0x06 0x75 0x06 0x58 0x06 0x43 0x06 0x33 0x06 0x1d 0x06 0xf3 0x05 0xa1 0x05 0x88 0x05 0x6a 0x05 0x9b 0x02 0x67 0x08 0x00 0x08 0x99 0x07 0x32 0x07 0xcb 0x06 0x64 0x06 0xfc 0x05 0x95 0x05 0x2e 0x05 0xc7 0x04 0x60 0x04 0xf9 0x03 0x92 0x03 0x2a 0x03 0xc3 0x02 0x5c 0x02 0xf5 0x01 0x8e 0x01 0x26 0x01 0xbf 0x00 0x58 0x00 0xf8 0x0f 0xfe 0x29 0xdc 0x29 0x8a 0x29 0x4d 0x29 0x28 0x1f 0x23 0x10 0x21 0x21 0x14 0x21 0xf3 0xf7 0xe6 0xf7 0xda 0xde 0xca 0xd4 0xd3 0xd4 0x40 0x80 0x26 0x33 0x26 0x40 0x26 0x5c 0x26 0x5c 0x26 0x5c 0xff 0xff 0x02 0x05 0x14 0x0b 0x03 0x12 0x06 0x1c 0x0c 0x1c 0x10 0x1c 0x1f 0x1f 0x38 0x38 0x38 0x40 0x40 0x3f 0x40 0x3f 0x3f 0x3f 0x40 0x41 0x3d 0x39 0x3a 0x3b 0x3c 0x3e 0x42 0x55 0x7b 0xa4 0x0f 0xf0 0x0a 0x00 0x00>;
		fuelgauge,fuel_alert_soc = <0x01>;
		fuelgauge,model_type = <0x01>;
		fuelgauge,raw_100_vbat = <0x10d3 0x10b1 0x1099>;
		fuelgauge,type_str = "SDI";
		status = "disable";
	};

	s6d7aa0_hd {
		dispif_resol = <0x2d0 0x500>;
		linux,phandle = <0x60>;
		mode = <0x00>;
		panel_name = "s6d7aa0";
		phandle = <0x60>;
		resolution = <0x2d0 0x500>;
		size = <0x3e 0x6e>;
		timing,decon_h-porch = <0x70 0xaf 0x1c>;
		timing,decon_v-porch = <0x0c 0x10 0x04>;
		timing,dsi-escape-clk = <0x10>;
		timing,dsi-hs-clk = <0x1e9>;
		timing,dsim_h-porch = <0x70 0x60 0x1c>;
		timing,dsim_v-porch = <0x0c 0x10 0x04>;
		timing,pms = <0x04 0x12d 0x02>;
		timing,refresh = <0x3c>;
	};

	scsc_wifibt@10580000 {
		compatible = "samsung,scsc_wifibt";
		interrupt-names = "MBOX\0ALIVE\0WDOG";
		interrupts = <0x00 0x178 0x04 0x00 0x15 0x04 0x00 0x1dc 0x04>;
		reg = <0x00 0x10580000 0x180>;
		samsung,syscon-cmu_fsys = <0x62>;
		samsung,syscon-phandle = <0x0e>;
		status = "okay";
		usbpll,owner = "y";
		usbpll,udelay = <0x14>;
	};

	sec_thermistor@0 {
		adc_array = <0x11d 0x128 0x132 0x13d 0x147 0x152 0x15e 0x169 0x175 0x180 0x18c 0x198 0x1a4 0x1b1 0x1bd 0x1c9 0x1da 0x1eb 0x1fc 0x20d 0x21d 0x233 0x248 0x25d 0x272 0x288 0x29c 0x2b2 0x2c7 0x2dc 0x2f1 0x308 0x31e 0x336 0x34c 0x364 0x382 0x3a0 0x3be 0x3dc 0x3fa 0x41b 0x43c 0x45d 0x47e 0x49f 0x4c1 0x4e3 0x506 0x528 0x54a 0x573 0x59b 0x5c4 0x5ec 0x615 0x643 0x671 0x6a0 0x6cf 0x6fd 0x727 0x752 0x77d 0x7a7 0x7d1 0x801 0x831 0x861 0x892 0x8c2 0x8f3 0x924 0x955 0x985 0x9b5 0x9e3 0xa10 0xa3e 0xa6b 0xa99 0xac3 0xaed 0xb16 0xb40 0xb6a 0xb95 0xbbf 0xbea 0xc14 0xc3f 0xc60 0xc81 0xca3 0xcc4 0xce5 0xd02 0xd20 0xd3d 0xd5b 0xd78 0xd8e 0xda4 0xdba 0xdd0 0xde6 0xdfe 0xe17 0xe2f 0xe48 0xe60>;
		compatible = "samsung,sec-ap-thermistor";
		io-channel-names = "adc-ap-temp";
		io-channel-ranges;
		io-channels = <0x43 0x00>;
		status = "okay";
		temp_array = <0x384 0x37a 0x370 0x366 0x35c 0x352 0x348 0x33e 0x334 0x32a 0x320 0x316 0x30c 0x302 0x2f8 0x2ee 0x2e4 0x2da 0x2d0 0x2c6 0x2bc 0x2b2 0x2a8 0x29e 0x294 0x28a 0x280 0x276 0x26c 0x262 0x258 0x24e 0x244 0x23a 0x230 0x226 0x21c 0x212 0x208 0x1fe 0x1f4 0x1ea 0x1e0 0x1d6 0x1cc 0x1c2 0x1b8 0x1ae 0x1a4 0x19a 0x190 0x186 0x17c 0x172 0x168 0x15e 0x154 0x14a 0x140 0x136 0x12c 0x122 0x118 0x10e 0x104 0xfa 0xf0 0xe6 0xdc 0xd2 0xc8 0xbe 0xb4 0xaa 0xa0 0x96 0x8c 0x82 0x78 0x6e 0x64 0x5a 0x50 0x46 0x3c 0x32 0x28 0x1e 0x14 0x0a 0x00 0xfffffff6 0xffffffec 0xffffffe2 0xffffffd8 0xffffffce 0xffffffc4 0xffffffba 0xffffffb0 0xffffffa6 0xffffff9c 0xffffff92 0xffffff88 0xffffff7e 0xffffff74 0xffffff6a 0xffffff60 0xffffff56 0xffffff4c 0xffffff42 0xffffff38>;
	};

	sec_vib {
		compatible = "sec_vib";

		sec_vib_pdata {
			sec_vib,ldo_en = <0x22 0x03 0x00>;
			sec_vib,ldo_type = <0x01>;
			sec_vib,max_timeout = <0x2710>;
			status = "okay";
		};
	};

	secgpio_dvs {
		compatible = "samsung,exynos7570-secgpio-dvs";
		status = "okay";
	};

	shmem@90000000 {
		compatible = "samsung,exynos-shm_ipc";
		shmem,ipc_offset = <0x5800000>;
		shmem,ipc_size = <0x400000>;
	};

	sound {
		compatible = "samsung,universal7570-cod9002x";
		mic-bias-mode = <0x01 0x01 0x02 0x00>;
		samsung,audio-codec = <0x46 0x46 0x46 0x87 0x46 0x87 0x87 0x46 0x46 0x46 0x46>;
		samsung,audio-cpu = <0x81 0x81 0x82 0x83 0x84 0x85 0x82 0x86 0x86 0x86 0x86>;
		samsung,auxdev = <0x88>;
		status = "okay";
	};

	speedy@10510000 {
		#address-cells = <0x01>;
		#size-cells = <0x00>;
		clock-names = "gate_speedy";
		clocks = <0x10 0x0b>;
		compatible = "samsung,exynos-speedy";
		interrupts = <0x00 0x174 0x00>;
		pinctrl-0 = <0x41>;
		pinctrl-names = "default";
		reg = <0x00 0x10510000 0x2000>;
		samsung,always-interrupt-high;
		status = "okay";

		cod9002x@03 {
			#io-channel-cells = <0x01>;
			btn-press-delay = <0x32>;
			but-zones-list = <0x44 0xe2 0x00 0xd9 0x44 0x246 0xda 0x128 0x44 0x73 0x129 0x1f2 0x44 0x72 0x1f3 0x3e8>;
			compatible = "codec,cod9002x";
			gpios = <0x20 0x01 0x01>;
			i2c-speedy-address;
			io-channel-names = "adc-jack";
			io-channel-ranges;
			io-channels = <0x43 0x02>;
			linux,phandle = <0x46>;
			mic-adc-range = <0x546>;
			mic-bias-ldo-voltage = <0x03>;
			mic-bias1-voltage = <0x01>;
			mic-bias2-voltage = <0x01>;
			phandle = <0x46>;
			pinctrl-names = "default";
			reg = <0x03>;
			use-btn-adc-mode;
			use-det-gdet-adc-mode;
			vdd-supply = <0x42>;
		};

		fimc_is_flash@06 {
			compatible = "samsung,sensor-flash-i2c";
			factory_current = <0xa0>;
			flash-gpio = <0x22 0x00 0x00>;
			flash_current = <0x3e8>;
			i2c-speedy-address;
			id = <0x00>;
			movie_current = <0xa0>;
			preflash_current = <0xa0>;
			reg = <0x06>;
			torch_current = <0x50>;
		};

		s2mpu06mfd@00 {
			cache_data = <0x01>;
			check_jigon = <0x00>;
			compatible = "samsung,s2mpu06mfd";
			i2c-speedy-address;
			init_time,hour = <0x0c>;
			init_time,mday = <0x01>;
			init_time,min = <0x00>;
			init_time,mon = <0x00>;
			init_time,sec = <0x00>;
			init_time,wday = <0x00>;
			init_time,year = <0x75>;
			pinctrl-0 = <0x45>;
			pinctrl-names = "default";
			reg = <0x00>;
			s2mpu06,irq-gpio = <0x22 0x05 0x00>;
			s2mpu06,wakeup = "enabled";
			samsung,codec-interrupt = <0x46>;
			smpl_en = "enabled";
			smpl_timer_val = <0x04>;
			wtsr_en = "enabled";
			wtsr_timer_val = <0x03>;

			regulators {

				BUCK1 {
					regulator-always-on;
					regulator-boot-on;
					regulator-expected-consumer = <0x06>;
					regulator-initial-mode = <0x01>;
					regulator-max-microvolt = <0x13d620>;
					regulator-min-microvolt = <0x7a120>;
					regulator-name = "BUCK1";
					regulator-ramp-delay = <0x2ee0>;
				};

				BUCK2 {
					regulator-always-on;
					regulator-boot-on;
					regulator-initial-mode = <0x03>;
					regulator-max-microvolt = <0x2ab980>;
					regulator-min-microvolt = "\0\f5";
					regulator-name = "BUCK2";
					regulator-ramp-delay = <0x2ee0>;
				};

				BUCK3 {
					regulator-always-on;
					regulator-boot-on;
					regulator-initial-mode = <0x03>;
					regulator-max-microvolt = <0x2ab980>;
					regulator-min-microvolt = "\0\f5";
					regulator-name = "BUCK3";
					regulator-ramp-delay = <0x2ee0>;
				};

				LDO1 {
					regulator-always-on;
					regulator-boot-on;
					regulator-initial-mode = <0x01>;
					regulator-max-microvolt = <0x13d620>;
					regulator-min-microvolt = <0x7a120>;
					regulator-name = "vdd_ldo1";
					regulator-ramp-delay = <0x2ee0>;
				};

				LDO13 {
					linux,phandle = <0x42>;
					phandle = <0x42>;
					regulator-always-on;
					regulator-boot-on;
					regulator-initial-mode = <0x03>;
					regulator-max-microvolt = <0x1e8480>;
					regulator-min-microvolt = "\0\f5";
					regulator-name = "vdd_ldo13";
					regulator-ramp-delay = <0x2ee0>;
				};

				LDO14 {
					regulator-initial-mode = <0x00>;
					regulator-max-microvolt = <0x337f98>;
					regulator-min-microvolt = <0x1b7740>;
					regulator-name = "vemmc";
					regulator-ramp-delay = <0x2ee0>;
				};

				LDO15 {
					regulator-initial-mode = <0x00>;
					regulator-max-microvolt = <0x1e8480>;
					regulator-min-microvolt = "\0\f5";
					regulator-name = "vqemmc";
					regulator-ramp-delay = <0x2ee0>;
				};

				LDO16 {
					regulator-initial-mode = <0x00>;
					regulator-max-microvolt = <0x337f98>;
					regulator-min-microvolt = <0x1b7740>;
					regulator-name = "vmmc";
					regulator-ramp-delay = <0x2ee0>;
				};

				LDO17 {
					regulator-initial-mode = <0x00>;
					regulator-max-microvolt = <0x1b7740>;
					regulator-min-microvolt = <0x1b7740>;
					regulator-name = "VDD18_CAM_SENSOR_IO";
					regulator-ramp-delay = <0x2ee0>;
				};

				LDO18 {
					regulator-initial-mode = <0x00>;
					regulator-max-microvolt = <0x2ab980>;
					regulator-min-microvolt = <0x2ab980>;
					regulator-name = "VDD28_CAM_AF";
					regulator-ramp-delay = <0x2ee0>;
				};

				LDO19 {
					regulator-max-microvolt = <0x325aa0>;
					regulator-min-microvolt = <0x325aa0>;
					regulator-name = "tsp_avdd";
				};

				LDO2 {
					linux,phandle = <0x2d>;
					phandle = <0x2d>;
					regulator-always-on;
					regulator-boot-on;
					regulator-initial-mode = <0x03>;
					regulator-max-microvolt = <0x1e8480>;
					regulator-min-microvolt = <0x16e360>;
					regulator-name = "vdd_ldo2";
					regulator-ramp-delay = <0x2ee0>;
				};

				LDO20 {
					regulator-boot-on;
					regulator-initial-mode = <0x03>;
					regulator-max-microvolt = <0x1b7740>;
					regulator-min-microvolt = <0x1b7740>;
					regulator-name = "LCD_1P8";
				};

				LDO21 {
					regulator-initial-mode = <0x00>;
					regulator-max-microvolt = <0x337f98>;
					regulator-min-microvolt = <0x1b7740>;
					regulator-name = "vdd_ldo21";
					regulator-ramp-delay = <0x2ee0>;
				};

				LDO22 {
					regulator-always-on;
					regulator-initial-mode = <0x03>;
					regulator-max-microvolt = <0x337f98>;
					regulator-min-microvolt = <0x1b7740>;
					regulator-name = "vdd_ldo22";
					regulator-ramp-delay = <0x2ee0>;
				};

				LDO23 {
					regulator-initial-mode = <0x00>;
					regulator-max-microvolt = <0x124f80>;
					regulator-min-microvolt = <0x124f80>;
					regulator-name = "VDD23_CAM_CORE_1P2";
					regulator-ramp-delay = <0x2ee0>;
				};

				LDO24 {
					regulator-initial-mode = <0x00>;
					regulator-max-microvolt = <0x2ab980>;
					regulator-min-microvolt = <0x2ab980>;
					regulator-name = "AVDD24_CAM_2P8";
					regulator-ramp-delay = <0x2ee0>;
				};

				LDO3 {
					regulator-always-on;
					regulator-boot-on;
					regulator-initial-mode = <0x03>;
					regulator-max-microvolt = <0x16e360>;
					regulator-min-microvolt = "\0\f5";
					regulator-name = "vdd_ldo3";
					regulator-ramp-delay = <0x2ee0>;
				};

				LDO4 {
					regulator-initial-mode = <0x00>;
					regulator-max-microvolt = <0x331df0>;
					regulator-min-microvolt = <0x19f0a0>;
					regulator-name = "vqmmc";
					regulator-ramp-delay = <0x2ee0>;
				};

				LDO5 {
					regulator-always-on;
					regulator-boot-on;
					regulator-initial-mode = <0x03>;
					regulator-max-microvolt = <0x331df0>;
					regulator-min-microvolt = <0x19f0a0>;
					regulator-name = "vdd_ldo5";
					regulator-ramp-delay = <0x2ee0>;
				};

				LDO6 {
					regulator-always-on;
					regulator-boot-on;
					regulator-initial-mode = <0x03>;
					regulator-max-microvolt = <0x13d620>;
					regulator-min-microvolt = <0x7a120>;
					regulator-name = "vdd_ldo6";
					regulator-ramp-delay = <0x2ee0>;
				};

				LDO7 {
					regulator-always-on;
					regulator-boot-on;
					regulator-initial-mode = <0x01>;
					regulator-max-microvolt = <0x13d620>;
					regulator-min-microvolt = "\0\f5";
					regulator-name = "vdd_ldo7";
					regulator-ramp-delay = <0x2ee0>;
				};

				LDO8 {
					regulator-always-on;
					regulator-boot-on;
					regulator-initial-mode = <0x01>;
					regulator-max-microvolt = <0x337f98>;
					regulator-min-microvolt = <0x1b7740>;
					regulator-name = "vdd_ldo8";
					regulator-ramp-delay = <0x2ee0>;
				};
			};

			s2mpu06-keys {

				button@1 {
					label = "pmic-keys: KEY_POWER";
					linux,code = <0x74>;
					wakeup = <0x01>;
				};
			};
		};
	};

	spi@100C0000 {
		#address-cells = <0x01>;
		#size-cells = <0x00>;
		clock-names = "spi\0spi_busclk0";
		clocks = <0x10 0x16a 0x10 0x17>;
		compatible = "samsung,exynos-spi";
		dma-names = "tx\0rx";
		interrupts = <0x00 0x1b2 0x00>;
		pinctrl-0 = <0x47>;
		pinctrl-names = "default";
		reg = <0x00 0x100c0000 0x100>;
		samsung,spi-fifosize = <0x100>;
		status = "disabled";
		swap-mode;
	};

	spi@13900000 {
		#address-cells = <0x01>;
		#size-cells = <0x00>;
		clock-names = "spi\0spi_busclk0";
		clocks = <0x10 0x16b 0x10 0x16>;
		compatible = "samsung,exynos-spi";
		dma-names = "tx\0rx";
		interrupts = <0x00 0x1b1 0x00>;
		pinctrl-0 = <0x48>;
		pinctrl-names = "default";
		reg = <0x00 0x13900000 0x100>;
		samsung,spi-fifosize = <0x40>;
		status = "disabled";
		swap-mode;
	};

	spi@13910000 {
		#address-cells = <0x01>;
		#size-cells = <0x00>;
		clock-names = "spi\0spi_busclk0";
		clocks = <0x10 0x15f 0x10 0x28>;
		compatible = "samsung,exynos-spi";
		dma-names = "tx\0rx";
		interrupts = <0x00 0x1ce 0x00>;
		pinctrl-0 = <0x49>;
		pinctrl-names = "default";
		reg = <0x00 0x13910000 0x100>;
		samsung,spi-fifosize = <0x20>;
		status = "disabled";
		swap-mode;
	};

	spi@13930000 {
		#address-cells = <0x01>;
		#size-cells = <0x00>;
		clock-names = "spi\0spi_busclk0";
		clocks = <0x10 0x160 0x10 0x29>;
		compatible = "samsung,exynos-spi";
		dma-names = "tx\0rx";
		interrupts = <0x00 0x1d2 0x00>;
		pinctrl-0 = <0x4a>;
		pinctrl-names = "default";
		reg = <0x00 0x13930000 0x100>;
		samsung,spi-fifosize = <0x20>;
		status = "disabled";
		swap-mode;
	};

	ss_tune {
		enable_fixed_rxeq_mode = <0x00 0x00>;
		enable_ssc = <0x01 0x01>;
		fix_rxeq_value = <0x04 0x04>;
		linux,phandle = <0x6c>;
		los_bias = <0x05 0x05>;
		los_mask_val = <0x104 0x104>;
		phandle = <0x6c>;
		set_crport_level_en = <0x00 0x00>;
		set_crport_mpll_charge_pump = <0x00 0x00>;
		ssc_range = <0x00 0x01>;
		status = "disabled";
		tx_boost_level = <0x04 0x04>;
		tx_deemphasis_3p5db = <0x18 0x18>;
		tx_deemphasis_6db = <0x18 0x18>;
		tx_deemphasis_mode = <0x01 0x01>;
		tx_swing_full = <0x7f 0x7f>;
		tx_swing_level = <0x01 0x01>;
		tx_swing_low = <0x7f 0x7f>;
	};

	system-controller@11C80000 {
		compatible = "samsung,exynos7570-pmu\0syscon";
		linux,phandle = <0x0e>;
		phandle = <0x0e>;
		reg = <0x00 0x11c80000 0x10000>;
	};

	timer {
		clock-frequency = <0x18cba80>;
		compatible = "arm,armv8-timer";
		interrupts = <0x01 0x0d 0xff01 0x01 0x0e 0xff01 0x01 0x0b 0xff01 0x01 0x0a 0xff01>;
		use-clocksource-only;
	};

	tmuctrl_CPUCL0@10130000 {
		compatible = "samsung,exynos7570-tmu";
		default_ptat_cont = <0x01>;
		interrupts = <0x00 0x1b3 0x00>;
		reg = <0x00 0x10130000 0x200>;
	};

	tmuctrl_G3D@10130000 {
		compatible = "samsung,exynos7570-tmu";
		default_ptat_cont = <0x01>;
		gpu_cooling_table = <0x00 0x00 0xcaa30 0x00 0x01 0xa2990 0x00 0x02 0x87028 0x00 0x03 0x65518 0x00 0x04 0xfffffffe>;
		gpu_idx_num = <0x05>;
		interrupts = <0x00 0x1b3 0x00>;
		reg = <0x00 0x10130000 0x200>;
	};

	uart@13800000 {
		clock-names = "gate_pclk1\0gate_uart1\0sclk_uart1";
		clocks = <0x10 0x169 0x10 0x15 0x10 0x15>;
		compatible = "samsung,exynos-uart";
		interrupts = <0x00 0x1a5 0x00>;
		pinctrl-0 = <0x11>;
		pinctrl-names = "default";
		reg = <0x00 0x13800000 0x100>;
		samsung,fifo-size = <0x10>;
		samsung,separate-uart-clk;
		status = "disabled";
	};

	uart@13820000 {
		clock-names = "gate_pclk2\0gate_uart2\0sclk_uart2";
		clocks = <0x10 0x168 0x10 0x14 0x10 0x14>;
		compatible = "samsung,exynos-uart";
		interrupts = <0x00 0x1a7 0x00>;
		pinctrl-0 = <0x12>;
		pinctrl-1 = <0x13>;
		pinctrl-names = "default\0uart_sleep";
		reg = <0x00 0x13820000 0x100>;
		samsung,alive-io;
		samsung,fifo-size = <0x100>;
		samsung,separate-uart-clk;
		status = "okay";
	};

	uart@13910000 {
		clock-names = "gate_pclk3\0gate_uart3\0sclk_uart3";
		clocks = <0x10 0x15f 0x10 0x28 0x10 0x28>;
		compatible = "samsung,exynos-uart";
		interrupts = <0x00 0x1cd 0x00>;
		pinctrl-0 = <0x14>;
		pinctrl-names = "default";
		reg = <0x00 0x13910000 0x100>;
		samsung,fifo-size = <0x20>;
		samsung,separate-uart-clk;
		status = "disabled";
	};

	uart@13930000 {
		clock-names = "gate_pclk4\0gate_uart4\0sclk_uart4";
		clocks = <0x10 0x160 0x10 0x29 0x10 0x29>;
		compatible = "samsung,exynos-uart";
		interrupts = <0x00 0x1d1 0x00>;
		pinctrl-0 = <0x15>;
		pinctrl-names = "default";
		reg = <0x00 0x13930000 0x100>;
		samsung,fifo-size = <0x20>;
		samsung,separate-uart-clk;
		status = "disabled";
	};

	uart_sel {
		compatible = "samsung,exynos-uart-sel";
		int_ap2cp_uart_noti = <0x0f>;
		mbx_ap2cp_united_status = <0x02>;
		sbi_uart_noti_mask = <0x01>;
		sbi_uart_noti_pos = <0x10>;
	};

	usb@13600000 {
		#address-cells = <0x02>;
		#size-cells = <0x01>;
		clock-names = "usbdrd20";
		clocks = <0x10 0x200>;
		compatible = "samsung,exynos7570-dwusb2";
		linux,phandle = <0x74>;
		phandle = <0x74>;
		ranges;
		reg = <0x00 0x13600000 0x10000>;
		status = "okay";

		dwc3 {
			compatible = "synopsys,dwc3";
			dr_mode = "otg";
			enable_sprs_transfer;
			interrupts = <0x00 0xe6 0x00>;
			is_not_vbus_pad;
			maximum-speed = "high-speed";
			phy-names = "usb2-phy\0usb3-phy";
			phys = <0x6a 0x00 0x6a 0x01>;
			reg = <0x00 0x13600000 0x10000>;
			suspend_clk_freq = <0x3fe56c0>;
		};
	};

	usb_notifier {
		compatible = "samsung,usb-notifier";
		udc = <0x74>;
	};

	usbphy@135c0000 {
		#phy-cells = <0x01>;
		clock-names = "usbdrd20\0phyumux\0usb_pll";
		clocks = <0x10 0x200 0x10 0x208 0x10 0x212>;
		compatible = "samsung,exynos7570-usbdrd-phy";
		hs_tune_info = <0x6b>;
		is_not_vbus_pad;
		linux,phandle = <0x6a>;
		phandle = <0x6a>;
		reg = <0x00 0x135c0000 0x100>;
		request_extrefclk;
		samsung,pmu-syscon = <0x0e>;
		ss_tune_info = <0x6c>;
		status = "okay";
		uart_io_share_enable = <0x01>;
		uart_io_share_mask = <0x01>;
		uart_io_share_offset = <0x6200>;
		use_additional_tuning;
	};

	usi@101D2000 {
		compatible = "samsung,exynos-usi";
		reg = <0x00 0x101d2000 0x100>;
		status = "disabled";
	};

	usi@101D3000 {
		compatible = "samsung,exynos-usi";
		reg = <0x00 0x101d3000 0x100>;
		status = "okay";
		usi_mode = "hsi2c1";
	};

	usim_det {
		compatible = "samsung,exynos-usim-detect";
		mbx_ap2cp_united_status = <0x02>;
		mif,int_usim0_det_level = <0x04>;
		mif,int_usim1_det_level = <0x05>;
		sbi_usim0_det_mask = <0x01>;
		sbi_usim0_det_pos = <0x11>;
		sbi_usim1_det_mask = <0x01>;
		sbi_usim1_det_pos = <0x12>;
	};

	watchdog@10170000 {
		clock-names = "rate_watchdog\0gate_watchdog";
		clocks = <0x10 0x173 0x10 0x173>;
		compatible = "samsung,exynos7-wdt";
		interrupts = <0x00 0x64 0x00>;
		reg = <0x00 0x10170000 0x100>;
		samsung,syscon-phandle = <0x0e>;
		timeout-sec = <0x1e>;
	};
};
